AUTOSAR XML (schema 4-2-1)
standard types defined: boolean, float32, float64, sint16, sint32, sint8, uint16, uint32, uint64, uint8, boolean_CompuMethod, boolean_DataConstr, float32_DataConstr, float64_DataConstr, sint16_DataConstr, sint32_DataConstr, sint8_DataConstr, uint16_DataConstr, uint32_DataConstr, uint64_DataConstr, uint8_DataConstr
package /ComponentTypes
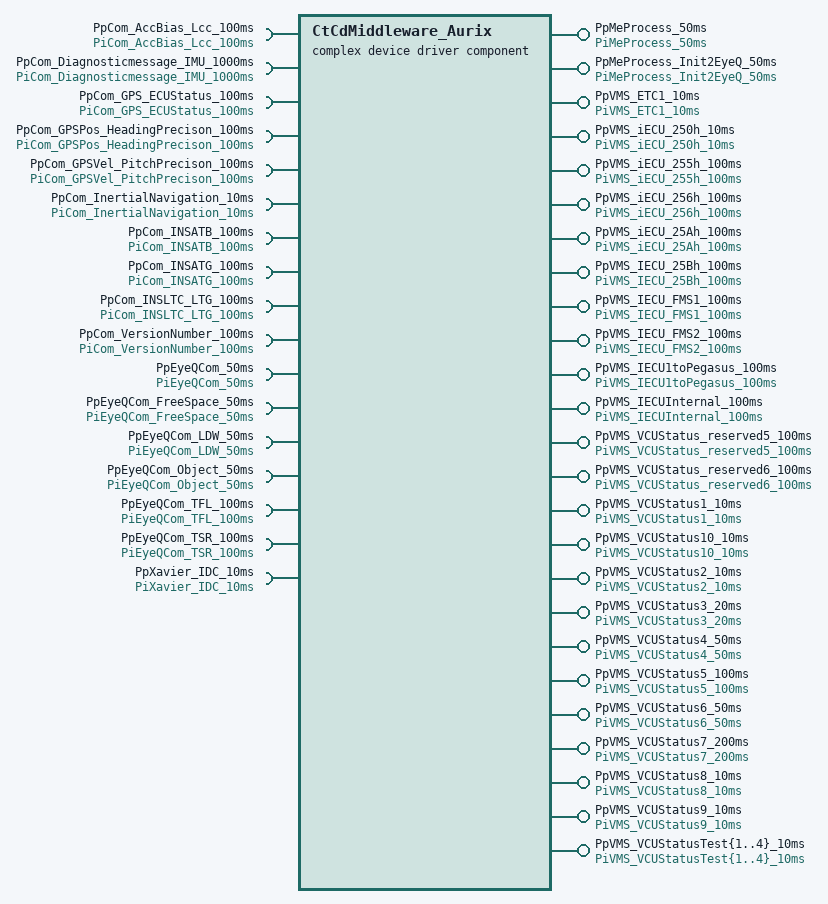
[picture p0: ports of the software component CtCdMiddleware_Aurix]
  complex device driver sw component type CtCdMiddleware_Aurix
    28 x provide port:
      PpMeProcess_50ms: provided-interface=PiMeProcess_50ms
        provided-com-specs:
          data-element=DeCurrentMode, init-value=constant-reference=C_RECORD_CurrentMode
          data-element=DeStartCalibration, init-value=0
      PpMeProcess_Init2EyeQ_50ms: provided-interface=PiMeProcess_Init2EyeQ_50ms
        provided-com-specs:
          data-element=DeCodingEnviroment, init-value=constant-reference=C_RECORD_CodingEnviroment
          data-element=DeIintISPCCoreVision, init-value=constant-reference=C_RECORD_IintISPCCoreVision
          data-element=DeInitEnvironment, init-value=constant-reference=C_RECORD_InitEnvironment
          data-element=DeInitGENERAL, init-value=constant-reference=C_RECORD_InitGENERAL
          data-element=DeInitTAC2, init-value=constant-reference=C_RECORD_TAC2
      PpVMS_ETC1_10ms: nonqueued-sender-com-spec{data-element=DeETC1, init-value=constant-reference=C_RECORD_ETC1}, provided-interface=PiVMS_ETC1_10ms
      PpVMS_iECU_250h_10ms: nonqueued-sender-com-spec{data-element=DeiECU_250h, init-value=constant-reference=C_RECORD_iECU_250h}, provided-interface=PiVMS_iECU_250h_10ms
      PpVMS_iECU_255h_100ms: nonqueued-sender-com-spec{data-element=DeiECU_255h, init-value=constant-reference=C_RECORD_iECU_255h}, provided-interface=PiVMS_iECU_255h_100ms
      PpVMS_iECU_256h_100ms: nonqueued-sender-com-spec{data-element=DeiECU_256h, init-value=constant-reference=C_RECORD_iECU_256h}, provided-interface=PiVMS_iECU_256h_100ms
      PpVMS_iECU_25Ah_100ms: nonqueued-sender-com-spec{data-element=DeiECU_25Ah, init-value=constant-reference=C_RECORD_iECU_25Ah}, provided-interface=PiVMS_iECU_25Ah_100ms
      PpVMS_IECU_25Bh_100ms: nonqueued-sender-com-spec{data-element=DeIECU_25Bh, init-value=constant-reference=C_RECORD_IECU_25Bh}, provided-interface=PiVMS_IECU_25Bh_100ms
      PpVMS_IECU_FMS1_100ms: nonqueued-sender-com-spec{data-element=DeIECU_FMS1, init-value=constant-reference=C_RECORD_IECU_FMS1}, provided-interface=PiVMS_IECU_FMS1_100ms
      PpVMS_IECU_FMS2_100ms: nonqueued-sender-com-spec{data-element=DeIECU_FMS2, init-value=constant-reference=C_RECORD_IECU_FMS2}, provided-interface=PiVMS_IECU_FMS2_100ms
      PpVMS_IECU1toPegasus_100ms: nonqueued-sender-com-spec{data-element=DeIECU1toPegasus, init-value=constant-reference=C_RECORD_IECU1toPegasus}, provided-interface=PiVMS_IECU1toPegasus_100ms
      PpVMS_IECUInternal_100ms: nonqueued-sender-com-spec{data-element=DeIECUInternal, init-value=constant-reference=C_RECORD_IECUInternal}, provided-interface=PiVMS_IECUInternal_100ms
      PpVMS_VCUStatus_reserved5_100ms: nonqueued-sender-com-spec{data-element=DeVCUStatus_reserved5, init-value=constant-reference=C_RECORD_VCUStatus_reserved5}, provided-interface=PiVMS_VCUStatus_reserved5_100ms
      PpVMS_VCUStatus_reserved6_100ms: nonqueued-sender-com-spec{data-element=DeVCUStatus_reserved6, init-value=constant-reference=C_RECORD_VCUStatus_reserved6}, provided-interface=PiVMS_VCUStatus_reserved6_100ms
      PpVMS_VCUStatus1_10ms: nonqueued-sender-com-spec{data-element=DeVCUStatus1, init-value=constant-reference=C_RECORD_VCUStatus1}, provided-interface=PiVMS_VCUStatus1_10ms
      PpVMS_VCUStatus10_10ms: nonqueued-sender-com-spec{data-element=DeVCUStatus10, init-value=constant-reference=C_RECORD_VCUStatus10}, provided-interface=PiVMS_VCUStatus10_10ms
      PpVMS_VCUStatus2_10ms: nonqueued-sender-com-spec{data-element=DeVCUStatus2, init-value=constant-reference=C_RECORD_VCUStatus2}, provided-interface=PiVMS_VCUStatus2_10ms
      PpVMS_VCUStatus3_20ms: nonqueued-sender-com-spec{data-element=DeVCUStatus3, init-value=constant-reference=C_RECORD_VCUStatus3}, provided-interface=PiVMS_VCUStatus3_20ms
      PpVMS_VCUStatus4_50ms: nonqueued-sender-com-spec{data-element=DeVCUStatus4, init-value=constant-reference=C_RECORD_VCUStatus4}, provided-interface=PiVMS_VCUStatus4_50ms
      PpVMS_VCUStatus5_100ms: nonqueued-sender-com-spec{data-element=DeVCUStatus5, init-value=constant-reference=C_RECORD_VCUStatus5}, provided-interface=PiVMS_VCUStatus5_100ms
      PpVMS_VCUStatus6_50ms: nonqueued-sender-com-spec{data-element=DeVCUStatus6, init-value=constant-reference=C_RECORD_VCUStatus6}, provided-interface=PiVMS_VCUStatus6_50ms
      PpVMS_VCUStatus7_200ms: nonqueued-sender-com-spec{data-element=DeVCUStatus7, init-value=constant-reference=C_RECORD_VCUStatus7}, provided-interface=PiVMS_VCUStatus7_200ms
      PpVMS_VCUStatus8_10ms: nonqueued-sender-com-spec{data-element=DeVCUStatus8, init-value=constant-reference=C_RECORD_VCUStatus8}, provided-interface=PiVMS_VCUStatus8_10ms
      PpVMS_VCUStatus9_10ms: nonqueued-sender-com-spec{data-element=DeVCUStatus9, init-value=constant-reference=C_RECORD_VCUStatus9}, provided-interface=PiVMS_VCUStatus9_10ms
      PpVMS_VCUStatusTest{1..4}_10ms: nonqueued-sender-com-spec{data-element=DeVCUStatusTest{1..4}, init-value=constant-reference=C_RECORD_VCUStatusTest{1..4}}, provided-interface=PiVMS_VCUStatusTest{1..4}_10ms
    17 x require port:
      PpCom_AccBias_Lcc_100ms: nonqueued-receiver-com-spec{data-element=DeAccBias_Lcc, filter=data-filter-type=ALWAYS, init-value=constant-reference=C_RECORD_AccBias_Lcc}, required-interface=PiCom_AccBias_Lcc_100ms
      PpCom_Diagnosticmessage_IMU_1000ms: nonqueued-receiver-com-spec{data-element=DeDiagnosticmessage_IMU, filter=data-filter-type=ALWAYS, init-value=constant-reference=C_RECORD_Diagnosticmessage_IMU}, required-interface=PiCom_Diagnosticmessage_IMU_1000ms
      PpCom_GPS_ECUStatus_100ms: nonqueued-receiver-com-spec{data-element=DeGPS_ECUStatus, filter=data-filter-type=ALWAYS, init-value=constant-reference=C_RECORD_GPS_ECUStatus}, required-interface=PiCom_GPS_ECUStatus_100ms
      PpCom_GPSPos_HeadingPrecison_100ms: nonqueued-receiver-com-spec{data-element=DeGPSPos_HeadingPrecison, filter=data-filter-type=ALWAYS, init-value=constant-reference=C_RECORD_GPSPos_HeadingPrecison}, required-interface=PiCom_GPSPos_HeadingPrecison_100ms
      PpCom_GPSVel_PitchPrecison_100ms: nonqueued-receiver-com-spec{data-element=DeGPSVel_PitchPrecison, filter=data-filter-type=ALWAYS, init-value=constant-reference=C_RECORD_GPSVel_PitchPrecison}, required-interface=PiCom_GPSVel_PitchPrecison_100ms
      PpCom_InertialNavigation_10ms: nonqueued-receiver-com-spec{data-element=DeInertialNavigation, filter=data-filter-type=ALWAYS, init-value=constant-reference=C_RECORD_InertialNavigation}, required-interface=PiCom_InertialNavigation_10ms
      PpCom_INSATB_100ms: nonqueued-receiver-com-spec{data-element=DeINSATB, filter=data-filter-type=ALWAYS, init-value=constant-reference=C_RECORD_INSATB}, required-interface=PiCom_INSATB_100ms
      PpCom_INSATG_100ms: nonqueued-receiver-com-spec{data-element=DeINSATG, filter=data-filter-type=ALWAYS, init-value=constant-reference=C_RECORD_INSATG}, required-interface=PiCom_INSATG_100ms
      PpCom_INSLTC_LTG_100ms: nonqueued-receiver-com-spec{data-element=DeINSLTC_LTG, filter=data-filter-type=ALWAYS, init-value=constant-reference=C_RECORD_INSLTC_LTG}, required-interface=PiCom_INSLTC_LTG_100ms
      PpCom_VersionNumber_100ms: nonqueued-receiver-com-spec{data-element=DeVersionNumber, filter=data-filter-type=ALWAYS, init-value=constant-reference=C_RECORD_VersionNumber}, required-interface=PiCom_VersionNumber_100ms
      PpEyeQCom_50ms: required-interface=PiEyeQCom_50ms
        required-com-specs:
          data-element=DeMeCommon_E, filter=data-filter-type=ALWAYS, init-value=constant-reference=C_RECORD_MeCommon_E
          data-element=DeMeConstructionArea_E, filter=data-filter-type=ALWAYS, init-value=constant-reference=C_RECORD_ConstructionArea_E
          data-element=DeMeHLB_E, filter=data-filter-type=ALWAYS, init-value=constant-reference=C_RECORD_HLB_E
          data-element=DeMeLane_Support_E, filter=data-filter-type=ALWAYS, init-value=constant-reference=C_RECORD_Lane_Support_E
          data-element=DeMeLaneAssignment_E, filter=data-filter-type=ALWAYS, init-value=constant-reference=C_RECORD_MeLaneAssignment
          data-element=PiEyeQCom_50ms/DeMeLDW_E, filter=data-filter-type=ALWAYS, init-value=constant-reference=C_RECORD_LDW_E
          data-element=DeMeLS_ADV_E, filter=data-filter-type=ALWAYS, init-value=constant-reference=C_RECORD_MeLS_ADV_E
          data-element=DeMeLS_Road_Edge_E, filter=data-filter-type=ALWAYS, init-value=constant-reference=C_RECORD_LS_Road_Edge_E
          data-element=DeMeSematicLines_E, filter=data-filter-type=ALWAYS, init-value=constant-reference=C_RECORD_MeSematicLines_E
          data-element=DeMeSematicMarks_E, filter=data-filter-type=ALWAYS, init-value=constant-reference=C_RECORD_MeSematicMark_E
          data-element=DeMeSL_Descrip_E, filter=data-filter-type=ALWAYS, init-value=constant-reference=C_RECORD_SL_Descrip_E
          data-element=DeRequestCalibrationStatus, filter=data-filter-type=ALWAYS, init-value=constant-reference=C_RequestCalibrationStatus
      PpEyeQCom_FreeSpace_50ms: required-interface=PiEyeQCom_FreeSpace_50ms
        required-com-specs:
          data-element=DeMeFreeSpace_E, filter=data-filter-type=ALWAYS, init-value=constant-reference=C_RECORD_MeFreeSpace_E
          data-element=DeMeFreeSpace_E_{1..5}, filter=data-filter-type=ALWAYS, init-value=constant-reference=C_RECORD_MeFreeSpace_E_x
      PpEyeQCom_LDW_50ms: nonqueued-receiver-com-spec{data-element=PiEyeQCom_LDW_50ms/DeMeLDW_E, filter=data-filter-type=ALWAYS, init-value=constant-reference=C_RECORD_MeLDW_E}, required-interface=PiEyeQCom_LDW_50ms
      PpEyeQCom_Object_50ms: required-interface=PiEyeQCom_Object_50ms
        required-com-specs:
          data-element=DeMeObjects_E, filter=data-filter-type=ALWAYS, init-value=constant-reference=C_RECORD_MeObjects_E
          data-element=DeMeObjects_E_{1..4}, filter=data-filter-type=ALWAYS, init-value=constant-reference=C_RECORD_MeObjects_E_x
      PpEyeQCom_TFL_100ms: nonqueued-receiver-com-spec{data-element=DeMeTFL, filter=data-filter-type=ALWAYS, init-value=constant-reference=C_RECORD_MeTFL_E}, required-interface=PiEyeQCom_TFL_100ms
      PpEyeQCom_TSR_100ms: required-interface=PiEyeQCom_TSR_100ms
        required-com-specs:
          data-element=DeMeTSR, filter=data-filter-type=ALWAYS, init-value=constant-reference=C_RECORD_MeTSR_E
          data-element=DeMeTSR_1, filter=data-filter-type=ALWAYS, init-value=constant-reference=C_RECORD_MeTSR_E_x
          data-element=DeMeTSR_2, filter=data-filter-type=ALWAYS, init-value=constant-reference=C_RECORD_MeTSR_E_x
      PpXavier_IDC_10ms: nonqueued-receiver-com-spec{data-element=DeIDC, filter=data-filter-type=ALWAYS, init-value=constant-reference=C_RECORD_IDC}, required-interface=PiXavier_IDC_10ms
    behavior CtCdMiddleware_Aurix_InternalBehavior
      7 x timing event:
        TMT_RCtCdMiddleware_Aurix_1000ms: start-on-event=RCtCdMiddleware_Aurix_1000ms, period=1
        TMT_RCtCdMiddleware_Aurix_100ms: start-on-event=RCtCdMiddleware_Aurix_100ms, period=0.1
        TMT_RCtCdMiddleware_Aurix_10ms: start-on-event=RCtCdMiddleware_Aurix_10ms, period=0.01
        TMT_RCtCdMiddleware_Aurix_200ms: start-on-event=RCtCdMiddleware_Aurix_200ms, period=0.2
        TMT_RCtCdMiddleware_Aurix_20ms: start-on-event=RCtCdMiddleware_Aurix_20ms, period=0.02
        TMT_RCtCdMiddleware_Aurix_30ms: start-on-event=RCtCdMiddleware_Aurix_30ms, period=0.03
        TMT_RCtCdMiddleware_Aurix_50ms: start-on-event=RCtCdMiddleware_Aurix_50ms, period=0.05
      7 x runnable:
        RCtCdMiddleware_Aurix_1000ms
          data-receive-point-by-arguments:
            access REC_PiCom_Diagnosticmessage_IMU_1000ms_DeDiagnosticmessage_IMU: accessed-variable=PpCom_Diagnosticmessage_IMU_1000ms.DeDiagnosticmessage_IMU
        RCtCdMiddleware_Aurix_100ms
          data-receive-point-by-arguments:
            12 x access:
              REC_PiCom_AccBias_Lcc_100ms_DeAccBias_Lcc: accessed-variable=PpCom_AccBias_Lcc_100ms.DeAccBias_Lcc
              REC_PiCom_GPS_ECUStatus_100ms_DeGPS_ECUStatus: accessed-variable=PpCom_GPS_ECUStatus_100ms.DeGPS_ECUStatus
              REC_PiCom_GPSPos_HeadingPrecison_100ms_DeGPSPos_HeadingPrecison: accessed-variable=PpCom_GPSPos_HeadingPrecison_100ms.DeGPSPos_HeadingPrecison
              REC_PiCom_GPSVel_PitchPrecison_100ms_DeGPSVel_PitchPrecison: accessed-variable=PpCom_GPSVel_PitchPrecison_100ms.DeGPSVel_PitchPrecison
              REC_PiCom_INSATB_100ms_DeINSATB: accessed-variable=PpCom_INSATB_100ms.DeINSATB
              REC_PiCom_INSATG_100ms_DeINSATG: accessed-variable=PpCom_INSATG_100ms.DeINSATG
              REC_PiCom_INSLTC_LTG_100ms_DeINSLTC_LTG: accessed-variable=PpCom_INSLTC_LTG_100ms.DeINSLTC_LTG
              REC_PiCom_VersionNumber_100ms_DeVersionNumber: accessed-variable=PpCom_VersionNumber_100ms.DeVersionNumber
              REC_PiEyeQCom_TFL_100ms_DeMeTFL: accessed-variable=PpEyeQCom_TFL_100ms.DeMeTFL
              REC_PiEyeQCom_TSR_100ms_DeMeTSR: accessed-variable=PpEyeQCom_TSR_100ms.DeMeTSR
              REC_PiEyeQCom_TSR_100ms_DeMeTSR_1: accessed-variable=PpEyeQCom_TSR_100ms.DeMeTSR_1
              REC_PiEyeQCom_TSR_100ms_DeMeTSR_2: accessed-variable=PpEyeQCom_TSR_100ms.DeMeTSR_2
          data-send-points:
            11 x access:
              SEND_PiVMS_iECU_255h_100ms_DeiECU_255h: accessed-variable=PpVMS_iECU_255h_100ms.DeiECU_255h
              SEND_PiVMS_iECU_256h_100ms_DeiECU_256h: accessed-variable=PpVMS_iECU_256h_100ms.DeiECU_256h
              SEND_PiVMS_iECU_25Ah_100ms_DeiECU_25Ah: accessed-variable=PpVMS_iECU_25Ah_100ms.DeiECU_25Ah
              SEND_PiVMS_IECU_25Bh_100ms_DeIECU_25Bh: accessed-variable=PpVMS_IECU_25Bh_100ms.DeIECU_25Bh
              SEND_PiVMS_IECU_FMS1_100ms_DeIECU_FMS1: accessed-variable=PpVMS_IECU_FMS1_100ms.DeIECU_FMS1
              SEND_PiVMS_IECU_FMS2_100ms_DeIECU_FMS2: accessed-variable=PpVMS_IECU_FMS2_100ms.DeIECU_FMS2
              SEND_PiVMS_IECU1toPegasus_100ms_DeIECU1toPegasus: accessed-variable=PpVMS_IECU1toPegasus_100ms.DeIECU1toPegasus
              SEND_PiVMS_IECUInternal_100ms_DeIECUInternal: accessed-variable=PpVMS_IECUInternal_100ms.DeIECUInternal
              SEND_PiVMS_VCUStatus_reserved5_100ms_DeVCUStatus_reserved5: accessed-variable=PpVMS_VCUStatus_reserved5_100ms.DeVCUStatus_reserved5
              SEND_PiVMS_VCUStatus_reserved6_100ms_DeVCUStatus_reserved6: accessed-variable=PpVMS_VCUStatus_reserved6_100ms.DeVCUStatus_reserved6
              SEND_PiVMS_VCUStatus5_100ms_DeVCUStatus5: accessed-variable=PpVMS_VCUStatus5_100ms.DeVCUStatus5
        RCtCdMiddleware_Aurix_10ms
          data-receive-point-by-arguments:
            access REC_PiCom_InertialNavigation_10ms_DeInertialNavigation: accessed-variable=PpCom_InertialNavigation_10ms.DeInertialNavigation
            access REC_PiXavier_IDC_10ms_DeIDC: accessed-variable=PpXavier_IDC_10ms.DeIDC
          data-send-points:
            11 x access:
              SEND_PiVMS_ETC1_10ms_DeETC1: accessed-variable=PpVMS_ETC1_10ms.DeETC1
              SEND_PiVMS_iECU_250h_10ms_DeiECU_250h: accessed-variable=PpVMS_iECU_250h_10ms.DeiECU_250h
              SEND_PiVMS_VCUStatus1_10ms_DeVCUStatus1: accessed-variable=PpVMS_VCUStatus1_10ms.DeVCUStatus1
              SEND_PiVMS_VCUStatus10_10ms_DeVCUStatus10: accessed-variable=PpVMS_VCUStatus10_10ms.DeVCUStatus10
              SEND_PiVMS_VCUStatus2_10ms_DeVCUStatus2: accessed-variable=PpVMS_VCUStatus2_10ms.DeVCUStatus2
              SEND_PiVMS_VCUStatus8_10ms_DeVCUStatus8: accessed-variable=PpVMS_VCUStatus8_10ms.DeVCUStatus8
              SEND_PiVMS_VCUStatus9_10ms_DeVCUStatus9: accessed-variable=PpVMS_VCUStatus9_10ms.DeVCUStatus9
              SEND_PiVMS_VCUStatusTest{1..4}_10ms_DeVCUStatusTest{1..4}: accessed-variable=PpVMS_VCUStatusTest{1..4}_10ms.DeVCUStatusTest{1..4}
        RCtCdMiddleware_Aurix_200ms
          data-send-points:
            access SEND_PiVMS_VCUStatus7_200ms_DeVCUStatus7: accessed-variable=PpVMS_VCUStatus7_200ms.DeVCUStatus7
        RCtCdMiddleware_Aurix_20ms
          data-send-points:
            access SEND_PiVMS_VCUStatus3_20ms_DeVCUStatus3: accessed-variable=PpVMS_VCUStatus3_20ms.DeVCUStatus3
        RCtCdMiddleware_Aurix_30ms
        RCtCdMiddleware_Aurix_50ms
          data-receive-point-by-arguments:
            24 x access:
              REC_PiEyeQCom_50ms_DeMeCommon_E: accessed-variable=PpEyeQCom_50ms.DeMeCommon_E
              REC_PiEyeQCom_50ms_DeMeConstructionArea_E: accessed-variable=PpEyeQCom_50ms.DeMeConstructionArea_E
              REC_PiEyeQCom_50ms_DeMeHLB_E: accessed-variable=PpEyeQCom_50ms.DeMeHLB_E
              REC_PiEyeQCom_50ms_DeMeLane_Support_E: accessed-variable=PpEyeQCom_50ms.DeMeLane_Support_E
              REC_PiEyeQCom_50ms_DeMeLaneAssignment_E: accessed-variable=PpEyeQCom_50ms.DeMeLaneAssignment_E
              REC_PiEyeQCom_50ms_DeMeLDW_E: accessed-variable=PpEyeQCom_50ms.DeMeLDW_E
              REC_PiEyeQCom_50ms_DeMeLS_ADV_E: accessed-variable=PpEyeQCom_50ms.DeMeLS_ADV_E
              REC_PiEyeQCom_50ms_DeMeLS_Road_Edge_E: accessed-variable=PpEyeQCom_50ms.DeMeLS_Road_Edge_E
              REC_PiEyeQCom_50ms_DeMeSematicLines_E: accessed-variable=PpEyeQCom_50ms.DeMeSematicLines_E
              REC_PiEyeQCom_50ms_DeMeSematicMarks_E: accessed-variable=PpEyeQCom_50ms.DeMeSematicMarks_E
              REC_PiEyeQCom_50ms_DeMeSL_Descrip_E: accessed-variable=PpEyeQCom_50ms.DeMeSL_Descrip_E
              REC_PiEyeQCom_50ms_DeRequestCalibrationStatus: accessed-variable=PpEyeQCom_50ms.DeRequestCalibrationStatus
              REC_PiEyeQCom_FreeSpace_50ms_DeMeFreeSpace_E: accessed-variable=PpEyeQCom_FreeSpace_50ms.DeMeFreeSpace_E
              REC_PiEyeQCom_FreeSpace_50ms_DeMeFreeSpace_E_{1..5}: accessed-variable=PpEyeQCom_FreeSpace_50ms.DeMeFreeSpace_E_{1..5}
              REC_PiEyeQCom_LDW_50ms_DeMeLDW_E: accessed-variable=PpEyeQCom_LDW_50ms.DeMeLDW_E
              REC_PiEyeQCom_Object_50ms_DeMeObjects_E: accessed-variable=PpEyeQCom_Object_50ms.DeMeObjects_E
              REC_PiEyeQCom_Object_50ms_DeMeObjects_E_{1..4}: accessed-variable=PpEyeQCom_Object_50ms.DeMeObjects_E_{1..4}
          data-send-points:
            9 x access:
              SEND_PiMeProcess_50ms_DeCurrentMode: accessed-variable=PpMeProcess_50ms.DeCurrentMode
              SEND_PiMeProcess_50ms_DeStartCalibration: accessed-variable=PpMeProcess_50ms.DeStartCalibration
              SEND_PiMeProcess_Init2EyeQ_50ms_DeCodingEnviroment: accessed-variable=PpMeProcess_Init2EyeQ_50ms.DeCodingEnviroment
              SEND_PiMeProcess_Init2EyeQ_50ms_DeIintISPCCoreVision: accessed-variable=PpMeProcess_Init2EyeQ_50ms.DeIintISPCCoreVision
              SEND_PiMeProcess_Init2EyeQ_50ms_DeInitEnvironment: accessed-variable=PpMeProcess_Init2EyeQ_50ms.DeInitEnvironment
              SEND_PiMeProcess_Init2EyeQ_50ms_DeInitGENERAL: accessed-variable=PpMeProcess_Init2EyeQ_50ms.DeInitGENERAL
              SEND_PiMeProcess_Init2EyeQ_50ms_DeInitTAC2: accessed-variable=PpMeProcess_Init2EyeQ_50ms.DeInitTAC2
              SEND_PiVMS_VCUStatus4_50ms_DeVCUStatus4: accessed-variable=PpVMS_VCUStatus4_50ms.DeVCUStatus4
              SEND_PiVMS_VCUStatus6_50ms_DeVCUStatus6: accessed-variable=PpVMS_VCUStatus6_50ms.DeVCUStatus6
  swc implementation CtCdMiddleware_Aurix_Implementation: behavior=CtCdMiddleware_Aurix_InternalBehavior
    code-descriptors:
      code Default: artifact-descriptors=autosar-engineering-object={short-label=Default, category=SWSRC}
package /Constants
  141 x constant specification:
    C_ARRAY_10_LaneAssignment: value-spec=10 x C_RECORD_LaneAssignment
    C_ARRAY_10_SematicLine: value-spec=10 x C_RECORD_SematicLine
    C_ARRAY_10_SLD: value-spec=10 x C_RECORD_SLD
    C_ARRAY_10_TFL: value-spec=10 x C_RECORD_TFL
    C_ARRAY_10_TSR: value-spec=10 x C_RECORD_TSR
    C_ARRAY_120_FSPoint: value-spec=120 x C_RECORD_FSPoint
    C_ARRAY_14_ConArea: value-spec=14 x C_RECORD_ConArea
    C_ARRAY_2_LS_Host_Line: value-spec=[C_RECORD_LS_Host_Line, C_RECORD_LS_Host_Line]
    C_ARRAY_20_MeObject: value-spec=20 x C_RECORD_MeObject
    C_ARRAY_20_SematicMark: value-spec=20 x C_RECORD_SematicMark
    C_ARRAY_20_TSR: value-spec=20 x C_RECORD_TSR
    C_ARRAY_24_FSPoint: value-spec=24 x C_RECORD_FSPoint
    C_ARRAY_4_LS_Adjacent_Line: value-spec=[C_RECORD_LS_Adjacent_Line, C_RECORD_LS_Adjacent_Line, C_RECORD_LS_Adjacent_Line, C_RECORD_LS_Adjacent_Line]
    C_ARRAY_4_LS_Road_Edge: value-spec=[C_RECORD_LS_Road_Edge, C_RECORD_LS_Road_Edge, C_RECORD_LS_Road_Edge, C_RECORD_LS_Road_Edge]
    C_ARRAY_5_MeObject: value-spec=5 x C_RECORD_MeObject
    C_ARRAY_8_MeLS_ADV_INTP: value-spec=8 x C_RECORD_MeLS_ADV_INTP
    C_ARRAY_UINT64_1_0: value-spec=[0, 0]
    C_RECORD_AccBias_Lcc: value-spec=fields=[AxBiassecinfo:0, AyBiassecinfo:0, AzBiassecinfo:0, Lccsecinfo:0]
    C_RECORD_Acce_AngularVel_X: value-spec=fields=[AccelerationXsecinfo:0, AngularRateXsecinfo:0]
    C_RECORD_Acce_AngularVel_Y: value-spec=fields=[AccelerationYsecinfo:0, AngularRateYsecinfo:0]
    C_RECORD_Acce_AngularVel_Z: value-spec=fields=[AccelerationZsecinfo:0, AngularRateZsecinfo:0]
    C_RECORD_ADVCommon: value-spec=fields=[LS_ADV_Zero_byte:0, LS_ADV_Protocol_Version:0, LS_ADV_Sync_ID:0, LS_INTP_Number:0, LS_CA_Is_Construction_Area:0, LS_Road_Vertical_Surface_Valid:0, Reserved_1:0, LS_Road_Vertical_Surface_VR:0, LS_Road_Vertical_Surface_C0:0, LS_Road_Vertical_Surface_C1:0, Reserved_2:0, PaddingGap8_1:0, PaddingGap16_2:0, PaddingGap16_3:0, PaddingGap16_4:0, LS_Road_Vertical_Surface_C2:0, Reserved_3:0, PaddingGap16_5:0, PaddingGap16_6:0, PaddingGap16_7:0, LS_Road_Vertical_Surface_C3:0, LS_Path_Pred_Valid:0, PaddingGap8_8:0, PaddingGap16_9:0, LS_Path_Pred_C0:0, Reserved_4:0, PaddingGap8_10:0, PaddingGap16_11:0, LS_Path_Pred_C1:0, LS_Path_Pred_C2:0, Reserved_5:0, PaddingGap16_12:0, PaddingGap16_13:0, LS_Path_Pred_C3:0, LS_Path_Pred_Conf:0, LS_Path_Pred_Half_Width:0, LS_INTP_Is_Highway_Merge_Left:0, LS_INTP_Is_Highway_Merge_Right:0, LS_INTP_Is_Highway_Exit_Left:0, LS_INTP_Is_Highway_Exit_Right:0, LS_INTP_Header_Buffer:0]
    C_RECORD_AtterrStatus2: value-spec=fields=[PitchStdsecinfo:0, RollStdsecinfo:0, VelDStdsecinfo:0, VelEStdsecinfo:0, VelNStdsecinfo:0, YawStdsecinfo:0]
    C_RECORD_CACommon: value-spec=fields=[CA_Zero_byte:0, CA_Protocol_Version:0, CA_Sync_ID:0, CA_Region_Code:0, CA_Objects_Count:0, PaddingGap16_1:0]
    C_RECORD_CodingEnviroment: value-spec=fields=[CEnvironment_Zero_byte:0, CEnvironment_Protocol_Version:0, PaddingGap16_1:0, CEnvironment_leftWheel:0, CEnvironment_rightWheel:0, CEnvironment_minHorizon_M:0, CEnvironment_maxHorizon_M:0, CEnvironment_minYaw_M:0, CEnvironment_maxYaw_M:0, Reserved_1:0, PaddingGap8_2:0, PaddingGap16_3:0, CEnvironment_camToRearAxle:0, CEnvironment_wheelRadius:0, Reserved_2:0, PaddingGap8_4:0, PaddingGap16_5:0, CEnvironment_refPX_Front_Bumper:0, CEnvironment_camToFrontAxle:0, CEnvironment_wheelWidth:0, CEnvironment_Max_Roll:0, Reserved_3:0, PaddingGap8_6:0, PaddingGap16_7:0]
    C_RECORD_ConArea: value-spec=fields=[CA_ID:0, CA_Frame_Age:0, CA_CA_Object_Type:0, PaddingGap8_1:0, CA_Long_Distance:0, CA_Long_DistancSTD:0, CA_Lat_Distance:0, CA_Lat_DistancSTD:0, CA_Height:0, CA_Height_STD:0, CA_Object_Height:0, CA_Object_Height_STD:0, CA_Object_Width:0, CA_Object_Width_STD:0, CA_Buffer:0, PaddingGap8_2:0, Reserved_1:0, Reserved_2:0, Reserved_3:0, Reserved_4:0, PaddingGap8_3:0]
    C_RECORD_ConstructionArea_E: value-spec=fields=[{short-label=stHeader, constant=C_RECORD_HEADER}, {short-label=stCACommon, constant=C_RECORD_CACommon}, {short-label=gstConArea, constant=C_ARRAY_14_ConArea}]
    C_RECORD_CurrentMode: value-spec=fields=[{short-label=stHeader, constant=C_RECORD_HEADER}, CurrentMode:0, PaddingGap8_1:0, PaddingGap16_2:0]
    C_RECORD_Diagnosticmessage_IMU: value-spec=fields=[DiffDataLinkBrokensecinfo:0, GNSSAntenasBrokensecinfo:0, GPSMsgErrInIMUsecinfo:0, IECUMsgErrInIMUsecinfo:0]
    C_RECORD_ETC1: value-spec=fields=[SrcAddressCtrlDeviceForTransCtrl:0, TransInputShaftSpeed:0, ProgressiveShiftDisable:0, EngineMomentaryOverspeedEnable:0, PercentClutchSlip:0, TransOutputShaftSpeed:0, TransShiftlnProcess:0, TransTorqueConverterLockupEngag:0, TransDrivelineEngaged:0]
    C_RECORD_FSPCommon: value-spec=fields=[FSP_Zero_byte:0, FSP_Protocol_Version:0, FSP_Sync_ID:0, FSP_Num_Of_Obstacles:0, Reserved_1:0, PaddingGap16_1:0]
    C_RECORD_FSPoint: value-spec=fields=[FSP_ID:0, FSP_Is_Valid:0, PaddingGap8_1:0, FSP_Existence_Prob:0, FSP_Emptiness_Prob:0, FSP_Classification_Type:0, FSP_Mobility_Status:0, PaddingGap16_2:0, FSP_Range:0, Reserved_2:0, PaddingGap16_3:0, FSP_Range_STD:0, FSP_Height:0, FSP_Height_STD:0, PaddingGap16_4:0, PaddingGap16_5:0, FSP_Azimuth_Angle:0, FSP_Buffer:0, PaddingGap16_6:0, PaddingGap16_7:0, PaddingGap16_8:0]
    C_RECORD_GPS_ECUStatus: value-spec=fields=[ECUWarningsecinfo:0, GPSHeadingStatussecinfo:0, GPSPosStatussecinfo:0, GPSStatussecinfo:0, GPSVelStatussecinfo:0, GPSWarningsecinfo:0, RTKDelaysecinfo:0, VehiclesStatussecinfo:0]
    C_RECORD_GPSPos_HeadingPrecison: value-spec=fields=[AltSigmaGPSsecinfo:0, HeadingSigmaGPSsecinfo:0, LatSigmaGPSsecinfo:0, LonSigmaGPSsecinfo:0]
    C_RECORD_GPSVel_PitchPrecison: value-spec=fields=[PitchSigmaGPSsecinfo:0, VeldownsigmaGPSsecinfo:0, VeleastsigmaGPSsecinfo:0, VelnorthsigmaGPSsecinfo:0]
    C_RECORD_HEADER: value-spec=fields=[{short-label=TimeStamp, constant=C_ARRAY_UINT64_1_0}, FrameID:0, PaddingGap8_1:0, Counter:0]
    C_RECORD_HLB_E: value-spec=fields=[HLB_Zero_byte:0, HLB_Protocol_Version:0, HLB_Sync_ID:0, HLB_Running_Mode:0, HLB_InActive_Reason:0, HLB_Decision:0, Reserved_1:0, PaddingGap8_1:0, HLB_Reason:0]
    C_RECORD_IDC: value-spec=fields=[{short-label=IDCDTC, constant=C_RECORD_IDCDTC}, {short-label=IDCStatus1, constant=C_RECORD_IDCStatus1}, {short-label=IDCStatus2, constant=C_RECORD_IDCStatus2}, {short-label=IDCStatus3, constant=C_RECORD_IDCStatus3}, {short-label=IDCStatus4, constant=C_RECORD_IDCStatus4}, {short-label=IDCStatus5, constant=C_RECORD_IDCStatus5}, {short-label=IDCStatus6, constant=C_RECORD_IDCStatus6}, {short-label=IDCStatus7, constant=C_RECORD_IDCStatus7}, {short-label=IDCStatus8, constant=C_RECORD_IDCStatus8}, {short-label=IDCStatus9, constant=C_RECORD_IDCStatus9}, {short-label=IDCStatus40, constant=C_RECORD_IDCStatus40}, {short-label=IDCStatus41, constant=C_RECORD_IDCStatus41}, {short-label=IDCStatus42, constant=C_RECORD_IDCStatus42}, {short-label=IDCStatus43, constant=C_RECORD_IDCStatus43}, {short-label=IDCStatus91, constant=C_RECORD_IDCStatus91}, {short-label=IDCStatus92, constant=C_RECORD_IDCStatus92}, {short-label=IDCStatus93, constant=C_RECORD_IDCStatus93}, {short-label=IDCStatus_reserved1, constant=C_RECORD_IDCStatus_reserved1}, {short-label=IDCStatus_reserved2, constant=C_RECORD_IDCStatus_reserved2}, {short-label=IDCStatus_reserved3, constant=C_RECORD_IDCStatus_reserved3}, {short-label=IDCStatus_reserved4, constant=C_RECORD_IDCStatus_reserved4}, {short-label=IDCStatus_reserved5, constant=C_RECORD_IDCStatus_reserved5}, {short-label=IDCStatus_reserved6, constant=C_RECORD_IDCStatus_reserved6}]
    C_RECORD_IDCDTC: value-spec=fields=[FailureBitPegsusInternal:0, FailureBitODFSPegsus:0, FailureBitODFSIECU2:0, FailureBitLoc:0]
    C_RECORD_IDCStatus_reserved1: value-spec=fields=[Byte_1:0, Byte_0:0]
    C_RECORD_IDCStatus_reserved2: value-spec=fields=[Byte_3:0, Byte_2:0]
    C_RECORD_IDCStatus_reserved3: value-spec=fields=[Byte_5:0, Byte_4:0]
    C_RECORD_IDCStatus_reserved4: value-spec=fields=[Byte_7:0, Byte_6:0]
    C_RECORD_IDCStatus_reserved5: value-spec=fields=[Byte_9:0, Byte_8:0]
    C_RECORD_IDCStatus_reserved6: value-spec=fields=[Byte_11:0, Byte_10:0]
    C_RECORD_IDCStatus1: value-spec=fields=[RoadFollowErrorHSC4:0, StrgWhlAngGrdCmdHSC4:0, StrgWhlAngCmdVHSC4:0, StrgWhlAngCmdHSC4:0, VehDeceCmdVHSC4:0, VehDeceCmdHSC4:0, EngToqReqVHSC4:0, EngToqReqHSC4:0, IDCReadyHSC4:0]
    C_RECORD_IDCStatus2: value-spec=fields=[Request_Auto:0, APP_Status:0, APACtlCmd:0, VehSpdMaxLmtHSC4:0, IDCDriveEnvironmentHSC4:0, ShifterPosReqHSC4:0, VehSpdReqHSC4:0, ActualYHSC4:0, ActualXHSC4:0]
    C_RECORD_IDCStatus3: value-spec=fields=[YawRateHSC4:0, HeadingAngleHSC4:0, LateralAcceHSC4:0, LongitudinalAcceHSC4:0]
    C_RECORD_IDCStatus4: value-spec=fields=[LongtAccReqHSC4:0, TrackCoefficiantX2VHSC4:0, TrackCoefficiantX2HSC4:0, TrackCoefficiantX1VHSC4:0, TrackCoefficiantX1HSC4:0]
    C_RECORD_IDCStatus40: value-spec=fields=[TrackCoefficiantX2HSC4_QJ:0, TrackCoefficiantX1HSC4_QJ:0]
    C_RECORD_IDCStatus41: value-spec=fields=[TrackCoefficiantX4HSC4_QJ:0, TrackCoefficiantX3HSC4_QJ:0]
    C_RECORD_IDCStatus42: value-spec=fields=[TrackCoefficiantX5HSC4_QJ:0, TrackCoefficiantY2HSC4_QJ:0, TrackCoefficiantY1HSC4_QJ:0]
    C_RECORD_IDCStatus43: value-spec=fields=[TrackCoefficiantY5HSC4_QJ:0, TrackCoefficiantY4HSC4_QJ:0, TrackCoefficiantY3HSC4_QJ:0]
    C_RECORD_IDCStatus5: value-spec=fields=[INSSlopeHSC4:0, TrackCoefficiantX4VHSC4:0, TrackCoefficiantX4HSC4:0, TrackCoefficiantX3HSC4:0, TrackCoefficiantX3VHSC4:0]
    C_RECORD_IDCStatus6: value-spec=fields=[TrackCoefficiantX5VHSC4:0, TrackCoefficiantX5HSC4:0, TrackCoefficiantY2VHSC4:0, TrackCoefficiantY2HSC4:0, TrackCoefficiantY1VHSC4:0, TrackCoefficiantY1HSC4:0]
    C_RECORD_IDCStatus7: value-spec=fields=[TrackCoefficiantY5HSC4:0, TrackCoefficiantY5VHSC4:0, TrackCoefficiantY4VHSC4:0, TrackCoefficiantY4HSC4:0, TrackCoefficiantY3VHSC4:0, TrackCoefficiantY3HSC4:0]
    C_RECORD_IDCStatus8: value-spec=fields=[DistanceToStop:0, Parmtrobg2HSC4:0, Parmtrobg1HSC4:0, BrkLghtsCmdHSC4:0, DangerousWrnngLghtCmdHSC4:0, DipdBeamLampsCmdHSC4:0, FrtFogLampCmdHSC4:0, HornCmdHSC4:0, LDircnLampsCmdHSC4:0, MainBeamLampsCmdHSC4:0, RDircnLampsCmdHSC4:0, RevsngLghtCmdHSC4:0, RrFogLampCmdHSC4:0, WidthLmpTaillightCmdHSC4:0, WiperCmdHSC4:0, WshrCmdHSC4:0]
    C_RECORD_IDCStatus9: value-spec=fields=GPSAngleHSC4:0
    C_RECORD_IDCStatus91: value-spec=fields=GPSLatitudeHSC4:8 x 0
    C_RECORD_IDCStatus92: value-spec=fields=GPSLongitudeHSC4:8 x 0
    C_RECORD_IDCStatus93: value-spec=fields=[RounterChangeHSC4:0, PathRadiumAvgHSC4:0, IDCAlvRCHSC4:0, CurveValidHSC4:0, PathRadiumMinHSC4:0, PredictedLengthHSC4:0]
    C_RECORD_iECU_250h: value-spec=fields=SA_AngleValue:0
    C_RECORD_iECU_255h: value-spec=fields=[iECU_PEGSUS_pilotWarning:0, iECU_PEGSUS_pilotStatus:0, iECU_pilotDisableInfo:0, iECU_pilot_OverrideIndicator:0]
    C_RECORD_iECU_256h: value-spec=fields=iECU_pilot_Steer_Override:0
    C_RECORD_iECU_25Ah: value-spec=fields=iECU_PEGSUS_AEBState:0
    C_RECORD_IECU_25Bh: value-spec=fields=LockandTwistSwitch:0
    C_RECORD_IECU_FMS1: value-spec=fields=[HighResolutionTripDistance_FMS:0, HghRsolTotalVehDistance_FMS:0]
    C_RECORD_IECU_FMS2: value-spec=fields=[Byte7:0, ResidualLiquidLevel_FMS:0]
    C_RECORD_IECU1toPegasus: value-spec=fields=[FailureBitODFSIECU1:0, FailureBitActor01:0]
    C_RECORD_IECUInternal: value-spec=fields=[Byte3:0, FailureBitIECU1Internal:0]
    C_RECORD_IintISPCCoreVision: value-spec=fields=[ISPC_Zero_byte:0, ISPC_Protocol_Version:0, Reserved_1:0, IVISION_Protocol_Version:0, IVISION_Zero_byte:0, Reserved_2:0, PaddingGap16_1:0]
    C_RECORD_InertialNavigation: value-spec=fields=[{short-label=Acce_AngularVel_X, constant=C_RECORD_Acce_AngularVel_X}, {short-label=Acce_AngularVel_Y, constant=C_RECORD_Acce_AngularVel_Y}, {short-label=Acce_AngularVel_Z, constant=C_RECORD_Acce_AngularVel_Z}, {short-label=AtterrStatus2, constant=C_RECORD_AtterrStatus2}, {short-label=INSAltitude_VelDown, constant=C_RECORD_INSAltitude_VelDown}, {short-label=INSLatitudeInfo, constant=C_RECORD_INSLatitudeInfo}, {short-label=INSLongitudeInfo, constant=C_RECORD_INSLongitudeInfo}, {short-label=NavStatus_Heading, constant=C_RECORD_NavStatus_Heading}, {short-label=Pitch_Roll, constant=C_RECORD_Pitch_Roll}, {short-label=PoserrStatus1, constant=C_RECORD_PoserrStatus1}, {short-label=StatusInfo, constant=C_RECORD_StatusInfo}, {short-label=VelNorthEast, constant=C_RECORD_VelNorthEast}]
    C_RECORD_InitEnvironment: value-spec=fields=[IEnvironment_Zero_byte:0, IEnvironment_General_Version:0, PaddingGap16_1:0, IEnvironment_leftWheel:0, IEnvironment_rightWheel:0, IEnvironment_refPX_Front_Bumper:0, IEnvironment_camToFrontAxle:0, IEnvironment_camToRearAxle:0, IEnvironment_wheelWidth:0, IEnvironment_wheelRadius:0, IEnvironment_minHorizon_M:0, IEnvironment_maxHorizon_M:0, IEnvironment_minYaw_M:0, IEnvironment_maxYaw_M:0, Reserved_1:0, Reserved_2:0, PaddingGap16_2:0, IEnvironment_Max_Roll:0, Reserved_3:0, PaddingGap8_3:0, PaddingGap16_4:0]
    C_RECORD_InitGENERAL: value-spec=fields=[IGeneral_Zero_byte:0, IGeneral_Vision_Protocol_Version:0, IGeneral_Region_Code:0, IGeneral_Driving_Side:0, IGeneral_Pitch:0, IGeneral_Yaw:0, IGeneral_Roll_Angle:0, IGeneral_Cam_Height:0, Reserved_1:0, IGeneral_HIL_Mode:0, PaddingGap16_1:0]
    C_RECORD_INSAltitude_VelDown: value-spec=fields=[AltitudeINSsecinfo:0, DownVelocitysecinfo:0]
    C_RECORD_INSATB: value-spec=fields=[ATB_pitchsecinfo:0, ATB_rollsecinfo:0, ATB_yawsecinfo:0]
    C_RECORD_INSATG: value-spec=fields=[ATG_pitchsecinfo:0, ATG_rollsecinfo:0, ATG_yawsecinfo:0]
    C_RECORD_INSLatitudeInfo: value-spec=fields=LatitudeINSsecinfo:8 x 0
    C_RECORD_INSLongitudeInfo: value-spec=fields=LongitudeINSsecinfo:8 x 0
    C_RECORD_INSLTC_LTG: value-spec=fields=[LTC_xsecinfo:0, LTC_ysecinfo:0, LTC_zsecinfo:0, LTG_xsecinfo:0, LTG_ysecinfo:0, LTG_zsecinfo:0]
    C_RECORD_LACommon: value-spec=fields=[LA_Zero_byte:0, LA_Protocol_Version:0, LA_Sync_ID:0, LA_Num_Of_Lanes_Close_Left:0, LA_Num_Of_Lanes_Close_Right:0, Reserved_1:0, LA_Num_Of_Lanes_Far_Left:0, LA_Num_Of_Lanes_Far_Right:0, LA_Has_Shoulder_Right_Close:0, PaddingGap8_1:0, PaddingGap16_2:0, LA_Shoulder_Right_Width_Close:0, LA_Has_Shoulder_Right_Far:0, PaddingGap8_3:0, PaddingGap16_4:0, LA_Shoulder_Right_Width_Far:0, LA_Header_Buffer:0, PaddingGap8_5:0, PaddingGap16_6:0]
    C_RECORD_Lane_Support_E: value-spec=fields=[{short-label=gstLS_Host_Line, constant=C_ARRAY_2_LS_Host_Line}, {short-label=stLSCommon, constant=C_RECORD_LSCommon}, {short-label=stHeader, constant=C_RECORD_HEADER}, PaddingGap16_1:0, PaddingGap16_2:0, {short-label=gstLS_Adjacent_Line, constant=C_ARRAY_4_LS_Adjacent_Line}]
    C_RECORD_LaneAssignment: value-spec=fields=[LA_Existence_Probability:0, LA_Role:0, LA_View:0, LA_Classification:0, PaddingGap8_1:0, LA_Classification_Probability:0, LA_Oncoming_Probability:0, LA_Preceding_Directions:0, PaddingGap8_2:0, PaddingGap16_3:0, LA_Direction_Probability:0, LA_Buffer:0]
    C_RECORD_LDW_E: value-spec=fields=[LDW_Zero_byte:0, LDW_Protocol_Version:0, LDW_Sync_ID:0, LDW_Line_Valid_Left:0, LDW_Line_Valid_Right:0, Reserved_1:0, LDW_Suppresion_Reason:0, LDW_Time_To_Warning_Left:0, LDW_Time_To_Warning_Right:0, LDW_Warning_Status_Left:0, LDW_Warning_Status_Right:0, Reserved_2:0, PaddingGap8_1:0]
    C_RECORD_LS_Adjacent_Line: value-spec=fields=[Lane_Track_ID:0, Age:0, PaddingGap16_1:0, Existence_Probability:0, Color:0, Prediction_Type:0, Reserved_13:0, PaddingGap8_2:0, View_Range_Start:0, View_Range_End:0, Reserved_14:0, Type_Class:0, DLM_Type:0, DECEL_Type:0, Line_Role:0, PaddingGap8_3:0, PaddingGap16_4:0, Marker_Width:0, Marker_Width_STD:0, Reserved_15:0, PaddingGap8_5:0, PaddingGap16_6:0, Dash_Average_Length:0, Dash_Average_Gap:0, Reserved_16:0, PaddingGap8_7:0, PaddingGap16_8:0, Line_C0:0, Line_C0_STD:0, Reserved_17:0, PaddingGap8_9:0, PaddingGap16_10:0, Estimated_Width:0, Line_C1:0, Line_C1_STD:0, Buffer:0, PaddingGap8_11:0, PaddingGap16_12:0, Line_C2:0, Line_C2_STD:0, Line_C3:0, Line_C3_STD:0]
    C_RECORD_LS_Host_Line: value-spec=fields=[Valid:0, Track_ID:0, Age:0, PaddingGap8_1:0, Existence_Probability:0, Color:0, Prediction_Type:0, Reserved_1:0, Type_Classification:0, DLM_Type:0, DECEL_Type:0, PaddingGap16_2:0, View_Range_Start:0, Reserved_2:0, PaddingGap8_3:0, PaddingGap16_4:0, View_Range_End:0, Crossing:0, PaddingGap8_5:0, PaddingGap16_6:0, Marker_Width:0, Marker_Width_STD:0, Reserved_3:0, PaddingGap8_7:0, PaddingGap16_8:0, Dash_Average_Length:0, Dash_Average_Gap:0, Reserved_4:0, PaddingGap8_9:0, PaddingGap16_10:0, Line_C0:0, Line_C0_STD:0, Reserved_5:0, PaddingGap8_11:0, PaddingGap16_12:0, Estimated_Width:0, Line_C1:0, Line_C1_STD:0, Reserved_6:0, PaddingGap8_13:0, PaddingGap16_14:0, PaddingGap16_15:0, PaddingGap16_16:0, Line_C2:0, Line_C2_STD:0, Line_C3:0, Line_C3_STD:0]
    C_RECORD_LS_Road_Edge: value-spec=fields=[LS_Road_Edge_ID:0, LS_Road_Edge_Age:0, PaddingGap16_1:0, LS_Road_Edge_Exist_Prob:0, LS_Road_Edge_Type:0, LS_Road_Edge_Prediction_Type:0, PaddingGap16_2:0, LS_Road_Edge_Height:0, LS_Road_Edge_View_Range_Start:0, Reserved_1:0, PaddingGap16_3:0, LS_Road_Edge_View_Range_End:0, PaddingGap16_4:0, PaddingGap16_5:0, LS_Road_Edge_Line_C3:0, LS_Road_Edge_Line_C3_STD:0, Reserved_2:0, PaddingGap16_6:0, LS_Road_Edge_Line_C2:0, LS_Road_Edge_Line_C2_STD:0, LS_Road_Edge_Line_C1:0, LS_Road_Edge_Line_C1_STD:0, Reserved_3:0, PaddingGap16_7:0, LS_Road_Edge_Line_C0:0, LS_Road_Edge_Line_C0_STD:0, LS_Road_Edge_Buffer:0, PaddingGap8_8:0, PaddingGap16_9:0, LS_Road_Edge_Height_STD:0, LS_Road_Edge_Host_Side:0, LS_Road_Edge_From_Host_Index:0, PaddingGap16_10:0, PaddingGap16_11:0, PaddingGap16_12:0]
    C_RECORD_LS_Road_Edge_E: value-spec=fields=[{short-label=gstrLS_Road_Edge, constant=C_ARRAY_4_LS_Road_Edge}, {short-label=strRoadEdgeCommon, constant=C_RECORD_RoadEdgeCommon}, {short-label=stHeader, constant=C_RECORD_HEADER}, PaddingGap16_1:0, PaddingGap16_2:0]
    C_RECORD_LSCommon: value-spec=fields=[Zero_byte:0, LS_Protocol_Version:0, LS_Sync_ID:0, LS_Adjacent_Number:0, LS_CA_Is_Construction_Area:0, LS_Header_Buffer_1:0, PaddingGap16_1:0]
    C_RECORD_MeCommon_E: value-spec=fields=[COM_Zero_byte:0, COM_Protocol_Version:0, COM_Sync_Frame_ID:0, PaddingGap8_1:0, PaddingGap16_2:0, PaddingGap16_3:0, COM_Frame_MCU_TS_Start:0, COM_Last_MCU_Sync_TS:0, Reserved_1:0, PaddingGap8_4:0, PaddingGap16_5:0, COM_Last_Clock_Sync_Error:0, COM_EyeQ_Frame_ID:0, COM_Cam_Frame_ID:0, COM_DayTime_Indicator:0, PaddingGap8_6:0, PaddingGap16_7:0, COM_DayTime_Ind_Quality:0, Reserved_2:0, PaddingGap16_8:0, Reserved_3:0, COM_HIL_Mode_Status:0, COM_Exposure_Type:0, PaddingGap16_9:0, {short-label=stHeader, constant=C_RECORD_HEADER}]
    C_RECORD_MeFreeSpace_E: value-spec=fields=[{short-label=stHeader, constant=C_RECORD_HEADER}, {short-label=FSPCommon, constant=C_RECORD_FSPCommon}, PaddingGap16_1:0, PaddingGap16_2:0, {short-label=gstFSPoint, constant=C_ARRAY_120_FSPoint}]
    C_RECORD_MeFreeSpace_E_x: value-spec=fields=[{short-label=stHeader, constant=C_RECORD_HEADER}, {short-label=FSPCommon, constant=C_RECORD_FSPCommon}, PaddingGap16_1:0, PaddingGap16_2:0, {short-label=gstFSPoint, constant=C_ARRAY_24_FSPoint}]
    C_RECORD_MeLaneAssignment: value-spec=fields=[{short-label=stHeader, constant=C_RECORD_HEADER}, {short-label=stLACommon, constant=C_RECORD_LACommon}, {short-label=gstLaneAssignment, constant=C_ARRAY_10_LaneAssignment}]
    C_RECORD_MeLDW_E: value-spec=fields=[LDW_Zero_byte:0, LDW_Protocol_Version:0, LDW_Sync_ID:0, LDW_Line_Valid_Left:0, LDW_Line_Valid_Right:0, Reserved_1:0, PaddingGap16_1:0, LDW_Suppresion_Reason:0, LDW_Time_To_Warning_Left:0, LDW_Time_To_Warning_Right:0, LDW_Warning_Status_Left:0, LDW_Warning_Status_Right:0, Reserved_2:0, PaddingGap8_2:0]
    C_RECORD_MeLS_ADV_E: value-spec=fields=[{short-label=stHeader, constant=C_RECORD_HEADER}, PaddingGap16_1:0, PaddingGap16_2:0, {short-label=stADVCommon, constant=C_RECORD_ADVCommon}, {short-label=gstINTP, constant=C_ARRAY_8_MeLS_ADV_INTP}]
    C_RECORD_MeLS_ADV_INTP: value-spec=fields=[LS_INTP_Type:0, LS_INTP_Is_Start:0, LS_INTP_Is_Valid:0, LS_INTP_Line_Role:0, LS_INTP_Lat_Distance:0, LS_INTP_Long_Distance:0, Reserved_6:0, LS_INTP_Buffer:0]
    C_RECORD_MeObject: value-spec=fields=[OBJ_ID:0, PaddingGap8_1:0, PaddingGap16_2:0, OBJ_Existence_Probability:0, OBJ_Is_Predicted:0, OBJ_Object_Class:0, OBJ_Object_Age:0, OBJ_Width:0, OBJ_Width_STD:0, OBJ_Length:0, OBJ_Length_STD:0, OBJ_Height:0, OBJ_Height_STD:0, OBJ_Absolute_Long_Velocity:0, OBJ_Absolute_Lat_Velocity:0, OBJ_Abs_Lat_Velocity_STD:0, OBJ_Relative_Long_Velocity:0, OBJ_Relative_Long_Velo_STD:0, OBJ_Relative_Lat_Velocity:0, OBJ_Relative_Lat_Velocity_STD:0, OBJ_Absolute_Lat_Acc:0, OBJ_Absolute_Lat_Acc_STD:0, OBJ_Long_Distance:0, OBJ_Long_Distance_STD:0, OBJ_Lat_Distance:0, OBJ_Lat_Distance_STD:0, OBJ_Absolute_Acceleration:0, OBJ_Absolute_Speed:0, OBJ_Motion_Status:0, OBJ_Motion_Category:0, OBJ_Motion_Oreintation:0, PaddingGap8_3:0, OBJ_Heading:0, OBJ_Brake_Light:0, OBJ_Turn_Indicator_Right:0, OBJ_Turn_Indicator_Left:0, OBJ_Light_Indicator_Validity:0, OBJ_Angle_Right:0, OBJ_Angle_Right_STD:0, OBJ_Angle_Left:0, OBJ_Angle_Left_STD:0, OBJ_Angle_Side:0, OBJ_Angle_Mid:0, OBJ_Angle_Mid_STD:0, OBJ_Top_Out_Of_Image:0, OBJ_Bottom_Out_Of_Image:0, OBJ_Right_Out_Of_Image:0, OBJ_Left_Out_Of_Image:0, OBJ_Angle_Rate:0, OBJ_Angle_Rate_STD:0, OBJ_Age_Seconds:0, OBJ_Is_In_Drivable_Area:0, OBJ_Is_VeryClose:0, OBJ_Lane_Assignment:0, OBJ_Camera:0, OBJ_Triggered_SDM:0, OBJ_Measuring_Status:0, OBJ_Lane_Assignment_V:0, OBJ_Top_Out_Of_Image_V:0, OBJ_Bottom_Out_Of_Image_V:0, OBJ_Age_Seconds_V:0, OBJ_Width_V:0, OBJ_Length_V:0, OBJ_Height_V:0, OBJ_Absolute_Long_Velocity_V:0, PaddingGap8_4:0, OBJ_Abs_Long_Velocity_STD:0, OBJ_Absolute_Lat_Velocity_V:0, OBJ_Absolute_Lat_Acc_V:0, OBJ_Absolute_Acceleration_V:0, OBJ_Inv_TTC_V:0, OBJ_Inv_TTC:0, OBJ_Relative_Long_Velocity_V:0, OBJ_Relative_Lat_Velocity_V:0, OBJ_Long_Distance_V:0, OBJ_Lat_Distance_V:0, OBJ_Absolute_Speed_V:0, OBJ_Heading_V:0, PaddingGap16_5:0, OBJ_Absolute_Speed_STD:0, OBJ_Heading_STD:0, OBJ_Angle_Rate_V:0, OBJ_Angle_Right_V:0, OBJ_Angle_Left_V:0, OBJ_Angle_Side_V:0, OBJ_Angle_Side_STD:0, OBJ_Angle_Mid_V:0, OBJ_Is_In_Drivable_Area_V:0, OBJ_Is_VeryClose_V:0, Reserved:14 x 0, PaddingGap8_6:0, PaddingGap16_7:0, OBJ_Absolute_Acce_STD:0]
    C_RECORD_MeObjects_E: value-spec=fields=[{short-label=stHeader, constant=C_RECORD_HEADER}, {short-label=stObjCommon, constant=C_RECORD_ObjCommon}, {short-label=gstMeObject, constant=C_ARRAY_20_MeObject}]
    C_RECORD_MeObjects_E_x: value-spec=fields=[{short-label=stHeader, constant=C_RECORD_HEADER}, {short-label=stObjCommon, constant=C_RECORD_ObjCommon}, {short-label=gstMeObject, constant=C_ARRAY_5_MeObject}]
    C_RECORD_MeSematicLines_E: value-spec=fields=[{short-label=stHeader, constant=C_RECORD_HEADER}, {short-label=stSLCommon, constant=C_RECORD_SLCommon}, {short-label=gstSematicLine, constant=C_ARRAY_10_SematicLine}]
    C_RECORD_MeSematicMark_E: value-spec=fields=[{short-label=stSMCommon, constant=C_RECORD_SMCommon}, {short-label=gstSematicMark, constant=C_ARRAY_20_SematicMark}, {short-label=stHeader, constant=C_RECORD_HEADER}]
    C_RECORD_MeTFL_E: value-spec=fields=[{short-label=gstrTFL, constant=C_ARRAY_10_TFL}, {short-label=strTFLCommon, constant=C_RECORD_TFLCommon}, {short-label=stHeader, constant=C_RECORD_HEADER}]
    C_RECORD_MeTSR_E: value-spec=fields=[{short-label=strTSRCommon, constant=C_RECORD_TSRCommon}, {short-label=gstrTSR, constant=C_ARRAY_20_TSR}, {short-label=stHeader, constant=C_RECORD_HEADER}]
    C_RECORD_MeTSR_E_x: value-spec=fields=[{short-label=strTSRCommon, constant=C_RECORD_TSRCommon}, {short-label=gstrTSR, constant=C_ARRAY_10_TSR}, {short-label=stHeader, constant=C_RECORD_HEADER}]
    C_RECORD_NavStatus_Heading: value-spec=fields=[ChannelInfosecinfo:0, CurrentGPSTimesecinfo:0, Headingsecinfo:0, NavStatussecinfo:0]
    C_RECORD_ObjCommon: value-spec=fields=[OBJ_Zero_byte:0, OBJ_Protocol_Version:0, OBJ_Sync_ID:0, OBJ_VRU_Count:0, OBJ_VD_Count:0, OBJ_General_OBJ_Count:0, OBJ_Animal_Count:0, OBJ_VD_CIPV_ID:0, OBJ_VD_CIPV_Lost:0, OBJ_VD_Allow_Acce:0, OBJ_VD_NIV_Right:0, OBJ_VD_NIV_Left:0, OBJ_Header_Buffer:0]
    C_RECORD_Pitch_Roll: value-spec=fields=[Pitchsecinfo:0, Rollsecinfo:0]
    C_RECORD_PoserrStatus1: value-spec=fields=[AltStdsecinfo:0, LatStdsecinfo:0, LonStdsecinfo:0]
    C_RECORD_RoadEdgeCommon: value-spec=fields=[LS_Road_Edge_Zero_byte:0, LS_Road_Edge_Protocol_Version:0, LS_Road_Edge_Sync_ID:0, LS_Road_Edge_Number:0, LS_Road_Edge_Header_Buffer:0, PaddingGap8_1:0, PaddingGap16_2:0]
    C_RECORD_SematicLine: value-spec=fields=[SL_Long_Dist:0, SL_Long_Dist_STD:0, SL_Probability:0, SL_Is_Relevant:0, PaddingGap8_1:0, PaddingGap16_2:0, SL_Width:0, SL_Length:0, SL_Measure_Status:0, PaddingGap8_3:0, PaddingGap16_4:0, SL_Angle:0, SL_Angle_STD:0, SL_Close_To_Junc:0, PaddingGap8_5:0, PaddingGap16_6:0, SL_Lat_Distance:0, SL_Color:0, SL_Type:0, SL_ID:0, PaddingGap8_7:0]
    C_RECORD_SematicMark: value-spec=fields=[SM_ID:0, PaddingGap8_1:0, PaddingGap16_2:0, SM_Type:0, Reserved_2:0, PaddingGap8_3:0, PaddingGap16_4:0, SM_Lat_Distance:0, SM_Long_Distance:0, SM_Confidence:0, SM_Buffer:0, PaddingGap16_5:0]
    C_RECORD_SL_Descrip_E: value-spec=fields=[{short-label=gstSLD, constant=C_ARRAY_10_SLD}, {short-label=stSLDCommon, constant=C_RECORD_SLDCommon}, {short-label=stHeader, constant=C_RECORD_HEADER}]
    C_RECORD_SLCommon: value-spec=fields=[SL_Zero_byte:0, SL_Protocol_Version:0, SL_Sync_ID:0, SL_Approved_Lines:0, SL_Header_Buffer:0, PaddingGap8_1:0, PaddingGap16_2:0]
    C_RECORD_SLD: value-spec=fields=[SLD_Existence_Probability:0, SLD_NonExistence_Probability:0, SLD_Role:0, SLD_View:0, SLD_Orientation:0, PaddingGap8_1:0, SLD_Orientation_Probability:0, SLD_Direction:0, PaddingGap8_2:0, PaddingGap16_3:0, SLD_Direction_Probability:0, SLD_Type:0, PaddingGap16_4:0, SLD_Type_Probability:0, SLD_Buffer:0, Reserved_2:0, PaddingGap16_5:0]
    C_RECORD_SLDCommon: value-spec=fields=[SLD_Num_Of_Lanes_Far_Left:0, SLD_Num_Of_Lanes_Far_Right:0, SLD_Has_Shoulder_Right_Close:0, PaddingGap8_1:0, SLD_Shoulder_Right_Width_Close:0, SLD_Has_Shoulder_Right_Far:0, PaddingGap8_2:0, PaddingGap16_3:0, SLD_Shoulder_Right_Width_Far:0, SLD_Header_Buffer:0, SLD_Zero_byte:0, SLD_Protocol_Version:0, SLD_Sync_ID:0, SLD_Num_Of_Lanes_Close_Left:0, SLD_Num_Of_Lanes_Close_Right:0, Reserved_1:0, PaddingGap8_4:0]
    C_RECORD_SMCommon: value-spec=fields=[SM_Zero_byte:0, SM_Protocol_Version:0, SM_Sync_ID:0, SM_Header_Buffer:0, SM_Approved_Marks:0, PaddingGap8_1:0, PaddingGap16_2:0]
    C_RECORD_StatusInfo: value-spec=fields=[ECUDelaysecinfo:0, ECUFreqsecinfo:0, GPSDelaysecinfo:0, GPSFreqsecinfo:0, INSDelaysecinfo:0, INSStatussecinfo:0, INSWarningsecinfo:0]
    C_RECORD_TAC2: value-spec=fields=[TAC_Zero_byte:0, TAC_Vision_Protocol_Version:1, TAC_Mode:1, TAC_BottomLeftSquare_0:0, TAC_BottomLeftSquare_1:1, TAC_Targets_Num:3, Reserved_1:0, PaddingGap8_1:0, TAC_TargetInfo_Lat_Distance_0:0.95, TAC_TargetInfo_Lat_Distance_1:0.95, TAC_TargetInfo_Height_0:1.93, TAC_targetInfo_height_1:1.93, TAC_Camera_Height:1.46, TAC_Camera_Z:5.158, TAC_Max_Horizon:0, TAC_Min_Horizon:0, TAC_Max_Yaw:248, TAC_Min_Yaw:0, TAC_Max_RollAngle:0.055, TAC_SquareSideSize:0.155, TAC_Bottom:0, Reserved_2:0, PaddingGap16_2:0]
    C_RECORD_TFL: value-spec=fields=[TFL_Existence_Probability:0, TFL_Relevance_Probability:0, TFL_Color:0, TFL_Mode:0, TFL_Relevance_Direction:0, Reserved_1:0, TFL_Rel_Dir_Quality:0, TFL_Shape:0, TFL_Structure_Orientation:0, PaddingGap16_1:0, TFL_Rel_Height:0, TFL_Rel_Height_STD:0, TFL_Lat_Distance:0, TFL_Lat_Distance_STD:0, TFL_Long_Distance:0, TFL_Long_Distance_STD:0, TFL_Width:0, TFL_Height:0, TFL_Width_STD:0, TFL_Height_STD:0, TFL_Camera_Source:0, TFL_Object_ID:0, TFL_LightBox_ID:0, Reserved_2:0, Reserved_3:0, PaddingGap8_2:0, PaddingGap16_3:0]
    C_RECORD_TFLCommon: value-spec=fields=[TFL_Zero_byte:0, TFL_Protocol_Version:0, TFL_Sync_ID:0, TFL_Number_Of_Objects:0, TFL_Header_Buffer:0, PaddingGap8_1:0, PaddingGap16_2:0]
    C_RECORD_TSR: value-spec=fields=[TSR_ID:0, TSR_Camera_Source:0, PaddingGap16_1:0, TSR_Sign_Name:0, TSR_Relevancy:0, TSR_Filter_Type:0, Reserved_3:0, TSR_Sup1_SignName:0, TSR_Sup1_Confidence:0, TSR_Sup2_SignName:0, PaddingGap8_2:0, PaddingGap16_3:0, TSR_Sup2_Confidence:0, Reserved_4:0, TSR_Sign_Shape:0, TSR_Sign_Structure:0, PaddingGap8_4:0, TSR_Confidence:0, TSR_Sign_Long_Distance:0, Reserved_5:0, TSR_Sign_Lateral_Distance:0, TSR_Sign_Height:0, Reserved_6:0, PaddingGap8_5:0, PaddingGap16_6:0, TSR_Sign_Long_Distance_STD:0, TSR_Sign_Lat_Distance_STD:0, Reserved_7:0, PaddingGap8_7:0, PaddingGap16_8:0, TSR_Sign_Height_STD:0, TSR_Sign_Panel_Width:0, Reserved_8:0, PaddingGap8_9:0, PaddingGap16_10:0, TSR_Sign_Panel_Height:0, TSR_Sign_Panel_Width_STD:0, TSR_Sign_Panel_Height_STD:0, Reserved_9:0, PaddingGap8_11:0, PaddingGap16_12:0, TSR_Tracking_Age:0]
    C_RECORD_TSRCommon: value-spec=fields=[Zero_byte:0, TSR_Protocol_Version:0, TSR_Sync_ID:0, Reserved_1:0, TSR_APR_Sign_Count:0, TSR_Filtered_Sign_Count:0, TSR_UnderTracking_Sign_Count:0, TSR_Header_Buffer:0, PaddingGap8_1:0, PaddingGap16_2:0]
    C_RECORD_VCUStatus_reserved5: value-spec=fields=[Byte9:0, Byte8:0]
    C_RECORD_VCUStatus_reserved6: value-spec=fields=[Byte11:0, Byte10:0]
    C_RECORD_VCUStatus1: value-spec=fields=[DrivemModeStssecinfo:0, DriveModeReqsecinfo:0, EnSpdsecinfo:0, EPSMotOtptToqsecinfo:0, keep1secinfo:0, PtBrkPdlDscrtInptStssecinfo:0, PtBrkPdlDscrtInptStsVsecinfo:0, SCUShiferLvrPossecinfo:0]
    C_RECORD_VCUStatus10: value-spec=fields=[RNonDrvnWhlRotlDistVHSC2:0, RNonDrvnWhlRotlDistPCHSC2:0, RDrvnWhlRotlDistVHSC2:0, RDrvnWhlRotlDistPlsCtrHSC2:0, LDrvnWhlRotlDistVHSC2:0, LNonDrvnWhlRotlDistPCHSC2:0, LNonDrvnWhlRotlDistVHSC2:0, LDrvnWhlRotlDistPlsCtrHSC2:0]
    C_RECORD_VCUStatus2: value-spec=fields=[StrgWhlAngHSC4:0, StrgWhlAngAlvRCHSC4:0, StrgWhlAngExtdPVHSC4:0, StrgWhlAngGrdHSC4:0, StrgWhlAngSnsrCalStsHSC4:0, StrgWhlAngSnsrChksmHSC4:0, StrgWhlAngSnsrFltHSC4:0, StrgWhlAngSnsrInidHSC4:0, StrgWhlAngSnsrMultCapbHSC4:0, StrgWhlAngVHSC4:0]
    C_RECORD_VCUStatus3: value-spec=fields=[SysVol_HSC4:0, EPBAppcnStsHSC4:0, VehSpdAvgVHSC4:0, VehSpdAvgHSC4:0, VSELongtAccVHSC4:0, VSELongtAccHSC4:0, VehDynYawRateVHSC4:0, VehDynYawRateHSC4:0, AirbagDplHSC4:0]
    C_RECORD_VCUStatus4: value-spec=fields=[VehLckngStaHSC4:0, FrtPsngDoorOpenStsHSC4:0, DrvrDoorOpenStsHSC4:0, VehInertiaSwTrigdHSC4:0, BrkPdlDrvrAppdPrsV_HSC4:0, BrkPdlDrvrAppdPrsAlvRC_HSC4:0, BrkPdlDrvrAppdPrs_HSC4:0]
    C_RECORD_VCUStatus5: value-spec=fields=[VehDeceLmtHSC4:0, VehAcceLmtHSC4:0, StrgWhlAngLmtHSC4:0, StrgWhlAngGrdLmtHSC4:0, RdFrictionCoefficientHSC4:0]
    C_RECORD_VCUStatus6: value-spec=fields=[WhlGndVelLDrvnsecinfo:0, WhlGndVelLDrvnVsecinfo:0, WhlGndVelLNonDrvnsecinfo:0, WhlGndVelLNonDrvnVsecinfo:0, WhlGndVelRDrvnsecinfo:0, WhlGndVelRDrvnVsecinfo:0, WhlGndVelRNonDrvnsecinfo:0, WhlGndVelRNonDrvnVsecinfo:0]
    C_RECORD_VCUStatus7: value-spec=fields=[ACInCarTemHSC4:0, FuelLvlPcntVHSC4:0, FuelLvlPcntHSC4:0, AmbtLghtLvlHSC4:0, OtsdAirTemCrValV_HSC4:0, OtsdAirTemCrVal_HSC4:0, BrkLghtsStaHSC4:0, DangerousWrnngLghtStaHSC4:0, DipdBeamLampsStaHSC4:0, FrtFogLampStaHSC4:0, HornStaHSC4:0, LDircnLampsStaHSC4:0, MainBeamLampsStaHSC4:0, RDircnLampsStaHSC4:0, RevsngLghtStaHSC4:0, RrFogLampStaHSC4:0, WidthLampAndTaillightStateHSC4:0, WiperStaHSC4:0, WshrStaHSC4:0]
    C_RECORD_VCUStatus8: value-spec=fields=[TimeDspFmtHSC2:0, SecsOfMinuteHSC2:0, MinuteOfHourHSC2:0, HourOfDayHSC2:0, CalendarYearHSC5:0, CalendarMonthHSC2:0, CalendarDayHSC2:0]
    C_RECORD_VCUStatus9: value-spec=fields=[VCUMainID:0, VCUAddonsID:0, Vehicleplatform:0, VCUstage:0, Projectname:0, Component:0, VehOdoHSC2:0]
    C_RECORD_VCUStatusTest1: value-spec=fields=[Test4:0, Test3:0, Test2:0, Test1:0]
    C_RECORD_VCUStatusTest2: value-spec=fields=[Test8:0, Test7:0, Test6:0, Test5:0]
    C_RECORD_VCUStatusTest3: value-spec=fields=[Test12:0, Test11:0, Test10:0, Test9:0]
    C_RECORD_VCUStatusTest4: value-spec=fields=[Test16:0, Test15:0, Test14:0, Test13:0]
    C_RECORD_VelNorthEast: value-spec=fields=[EastVelocitysecinfo:0, NorthVelocitysecinfo:0]
    C_RECORD_VersionNumber: value-spec=fields=[ARMAPPVersecinfo:0, ARMBLVersecinfo:0, DSPAPPVersecinfo:0, DSPBLVersecinfo:0]
    C_RequestCalibrationStatus: value-spec=0
package /DataTypes
  145 x impl type, all with sw-calibration-access=READ-ONLY, type-emitter=RTE:
    Dt_ARRAY_10_LaneAssignment: category=ARRAY
      element Element: array-size=10, array-size-semantics=FIXED-SIZE, implementation-data-type=Dt_RECORD_LaneAssignment
    Dt_ARRAY_10_SematicLine: category=ARRAY
      element Element: array-size=10, array-size-semantics=FIXED-SIZE, implementation-data-type=Dt_RECORD_SematicLine
    Dt_ARRAY_10_SLD: category=ARRAY
      element Element: array-size=10, array-size-semantics=FIXED-SIZE, implementation-data-type=Dt_RECORD_SLD
    Dt_ARRAY_10_TFL: category=ARRAY
      element Element: array-size=10, array-size-semantics=FIXED-SIZE, implementation-data-type=Dt_RECORD_TFL
    Dt_ARRAY_10_TSR: category=ARRAY
      element Element: array-size=10, array-size-semantics=FIXED-SIZE, implementation-data-type=Dt_RECORD_TSR
    Dt_ARRAY_120_FSPoint: category=ARRAY
      element Element: array-size=120, array-size-semantics=FIXED-SIZE, implementation-data-type=Dt_RECORD_FSPoint
    Dt_ARRAY_14_ConArea: category=ARRAY
      element Element: array-size=14, array-size-semantics=FIXED-SIZE, implementation-data-type=Dt_RECORD_ConArea
    Dt_ARRAY_14_uint8: category=ARRAY
      element Element: array-size=14, array-size-semantics=FIXED-SIZE, implementation-data-type=uint8
    Dt_ARRAY_2_LS_Host_Line: category=ARRAY
      element Element: array-size=2, array-size-semantics=FIXED-SIZE, implementation-data-type=Dt_RECORD_LS_Host_Line
    Dt_ARRAY_20_MeObject: category=ARRAY
      element Element: array-size=20, array-size-semantics=FIXED-SIZE, implementation-data-type=Dt_RECORD_MeObject
    Dt_ARRAY_20_SematicMark: category=ARRAY
      element Element: array-size=20, array-size-semantics=FIXED-SIZE, implementation-data-type=Dt_RECORD_SematicMark
    Dt_ARRAY_20_TSR: category=ARRAY
      element Element: array-size=20, array-size-semantics=FIXED-SIZE, implementation-data-type=Dt_RECORD_TSR
    Dt_ARRAY_24_FSPoint: category=ARRAY
      element Element: array-size=24, array-size-semantics=FIXED-SIZE, implementation-data-type=Dt_RECORD_FSPoint
    Dt_ARRAY_4_LS_Adjacent_Line: category=ARRAY
      element Element: array-size=4, array-size-semantics=FIXED-SIZE, implementation-data-type=Dt_RECORD_LS_Adjacent_Line
    Dt_ARRAY_4_LS_Road_Edge: category=ARRAY
      element Element: array-size=4, array-size-semantics=FIXED-SIZE, implementation-data-type=Dt_RECORD_LS_Road_Edge
    Dt_ARRAY_5_MeObject: category=ARRAY
      element Element: array-size=5, array-size-semantics=FIXED-SIZE, implementation-data-type=Dt_RECORD_MeObject
    Dt_ARRAY_8_GPSLatitudeHSC4: category=ARRAY
      element Element: array-size=8, array-size-semantics=FIXED-SIZE, implementation-data-type=uint8
    Dt_ARRAY_8_GPSLongitudeHSC4: category=ARRAY
      element Element: array-size=8, array-size-semantics=FIXED-SIZE, implementation-data-type=uint8
    Dt_ARRAY_8_LatitudeINSsecinfo: category=ARRAY
      element Element: array-size=8, array-size-semantics=FIXED-SIZE, implementation-data-type=uint8
    Dt_ARRAY_8_LongitudeINSsecinfo: category=ARRAY
      element Element: array-size=8, array-size-semantics=FIXED-SIZE, implementation-data-type=uint8
    Dt_ARRAY_8_MeLS_ADV_INTP: category=ARRAY
      element Element: array-size=8, array-size-semantics=FIXED-SIZE, implementation-data-type=Dt_RECORD_MeLS_ADV_INTP
    Dt_ARRAY_UINT64_1_0: category=ARRAY
      element Element: array-size=2, array-size-semantics=FIXED-SIZE, implementation-data-type=uint32
    Dt_RECORD_AccBias_Lcc: category=STRUCTURE
      4 x element, all with category=TYPE_REFERENCE, implementation-data-type=float32:
        AxBiassecinfo
        AyBiassecinfo
        AzBiassecinfo
        Lccsecinfo
    Dt_RECORD_Acce_AngularVel_X: category=STRUCTURE
      element AccelerationXsecinfo: implementation-data-type=float32
      element AngularRateXsecinfo: implementation-data-type=float32
    Dt_RECORD_Acce_AngularVel_Y: category=STRUCTURE
      element AccelerationYsecinfo: implementation-data-type=float32
      element AngularRateYsecinfo: implementation-data-type=float32
    Dt_RECORD_Acce_AngularVel_Z: category=STRUCTURE
      element AccelerationZsecinfo: implementation-data-type=float32
      element AngularRateZsecinfo: implementation-data-type=float32
    Dt_RECORD_ADVCommon: category=STRUCTURE
      41 x element, all with category=TYPE_REFERENCE:
        LS_ADV_Zero_byte: implementation-data-type=uint8
        LS_ADV_Protocol_Version: implementation-data-type=uint8
        LS_ADV_Sync_ID: implementation-data-type=uint8
        LS_INTP_Number: implementation-data-type=uint8
        LS_CA_Is_Construction_Area: implementation-data-type=boolean
        LS_Road_Vertical_Surface_Valid: implementation-data-type=boolean
        Reserved_1: implementation-data-type=uint8
        LS_Road_Vertical_Surface_VR: implementation-data-type=uint8
        LS_Road_Vertical_Surface_C0: implementation-data-type=float32
        LS_Road_Vertical_Surface_C1: implementation-data-type=float32
        Reserved_2: implementation-data-type=uint8
        PaddingGap8_1: implementation-data-type=uint8
        PaddingGap16_{2..4}: implementation-data-type=uint16
        LS_Road_Vertical_Surface_C2: implementation-data-type=float64
        Reserved_3: implementation-data-type=uint16
        PaddingGap16_{5..7}: implementation-data-type=uint16
        LS_Road_Vertical_Surface_C3: implementation-data-type=float64
        LS_Path_Pred_Valid: implementation-data-type=boolean
        PaddingGap8_8: implementation-data-type=uint8
        PaddingGap16_9: implementation-data-type=uint16
        LS_Path_Pred_C0: implementation-data-type=float32
        Reserved_4: implementation-data-type=uint8
        PaddingGap8_10: implementation-data-type=uint8
        PaddingGap16_11: implementation-data-type=uint16
        LS_Path_Pred_C1: implementation-data-type=float32
        LS_Path_Pred_C2: implementation-data-type=float64
        Reserved_5: implementation-data-type=uint32
        PaddingGap16_12: implementation-data-type=uint16
        PaddingGap16_13: implementation-data-type=uint16
        LS_Path_Pred_C3: implementation-data-type=float64
        LS_Path_Pred_Conf: implementation-data-type=float32
        LS_Path_Pred_Half_Width: implementation-data-type=float32
        LS_INTP_Is_Highway_Merge_Left: implementation-data-type=boolean
        LS_INTP_Is_Highway_Merge_Right: implementation-data-type=boolean
        LS_INTP_Is_Highway_Exit_Left: implementation-data-type=boolean
        LS_INTP_Is_Highway_Exit_Right: implementation-data-type=boolean
        LS_INTP_Header_Buffer: implementation-data-type=uint32
    Dt_RECORD_AtterrStatus2: category=STRUCTURE
      6 x element, all with category=TYPE_REFERENCE, implementation-data-type=float32:
        PitchStdsecinfo
        RollStdsecinfo
        VelDStdsecinfo
        VelEStdsecinfo
        VelNStdsecinfo
        YawStdsecinfo
    Dt_RECORD_CACommon: category=STRUCTURE
      6 x element, all with category=TYPE_REFERENCE:
        CA_Zero_byte: implementation-data-type=uint8
        CA_Protocol_Version: implementation-data-type=uint8
        CA_Sync_ID: implementation-data-type=sint16
        CA_Region_Code: implementation-data-type=uint8
        CA_Objects_Count: implementation-data-type=uint8
        PaddingGap16_1: implementation-data-type=uint16
    Dt_RECORD_CodingEnviroment: category=STRUCTURE
      24 x element, all with category=TYPE_REFERENCE:
        CEnvironment_Zero_byte: implementation-data-type=uint8
        CEnvironment_Protocol_Version: implementation-data-type=uint8
        PaddingGap16_1: implementation-data-type=uint16
        CEnvironment_leftWheel: implementation-data-type=float32
        CEnvironment_rightWheel: implementation-data-type=float32
        CEnvironment_minHorizon_M: implementation-data-type=sint16
        CEnvironment_maxHorizon_M: implementation-data-type=sint16
        CEnvironment_minYaw_M: implementation-data-type=sint16
        CEnvironment_maxYaw_M: implementation-data-type=uint16
        Reserved_1: implementation-data-type=uint8
        PaddingGap8_2: implementation-data-type=uint8
        PaddingGap16_3: implementation-data-type=uint16
        CEnvironment_camToRearAxle: implementation-data-type=float32
        CEnvironment_wheelRadius: implementation-data-type=float32
        Reserved_2: implementation-data-type=uint8
        PaddingGap8_4: implementation-data-type=uint8
        PaddingGap16_5: implementation-data-type=uint16
        CEnvironment_refPX_Front_Bumper: implementation-data-type=float32
        CEnvironment_camToFrontAxle: implementation-data-type=float32
        CEnvironment_wheelWidth: implementation-data-type=float32
        CEnvironment_Max_Roll: implementation-data-type=float32
        Reserved_3: implementation-data-type=uint8
        PaddingGap8_6: implementation-data-type=uint8
        PaddingGap16_7: implementation-data-type=uint16
    Dt_RECORD_ConArea: category=STRUCTURE
      21 x element, all with category=TYPE_REFERENCE:
        CA_ID: implementation-data-type=uint8
        CA_Frame_Age: implementation-data-type=uint8
        CA_CA_Object_Type: implementation-data-type=uint8
        PaddingGap8_1: implementation-data-type=uint8
        CA_Long_Distance: implementation-data-type=float32
        CA_Long_DistancSTD: implementation-data-type=float32
        CA_Lat_Distance: implementation-data-type=float32
        CA_Lat_DistancSTD: implementation-data-type=float32
        CA_Height: implementation-data-type=float32
        CA_Height_STD: implementation-data-type=float32
        CA_Object_Height: implementation-data-type=float32
        CA_Object_Height_STD: implementation-data-type=float32
        CA_Object_Width: implementation-data-type=float32
        CA_Object_Width_STD: implementation-data-type=float32
        CA_Buffer: implementation-data-type=uint8
        PaddingGap8_2: implementation-data-type=uint8
        Reserved_1: implementation-data-type=uint16
        Reserved_{2..4}: implementation-data-type=uint8
        PaddingGap8_3: implementation-data-type=uint8
    Dt_RECORD_ConstructionArea_E: category=STRUCTURE
      element stHeader: implementation-data-type=Dt_RECORD_HEADER
      element stCACommon: implementation-data-type=Dt_RECORD_CACommon
      element gstConArea: implementation-data-type=Dt_ARRAY_14_ConArea
    Dt_RECORD_CurrentMode: category=STRUCTURE
      4 x element, all with category=TYPE_REFERENCE:
        stHeader: implementation-data-type=Dt_RECORD_HEADER
        CurrentMode: implementation-data-type=uint8
        PaddingGap8_1: implementation-data-type=uint8
        PaddingGap16_2: implementation-data-type=uint16
    Dt_RECORD_Diagnosticmessage_IMU: category=STRUCTURE
      4 x element, all with category=TYPE_REFERENCE, implementation-data-type=uint8:
        DiffDataLinkBrokensecinfo
        GNSSAntenasBrokensecinfo
        GPSMsgErrInIMUsecinfo
        IECUMsgErrInIMUsecinfo
    Dt_RECORD_ETC1: category=STRUCTURE
      9 x element, all with category=TYPE_REFERENCE:
        SrcAddressCtrlDeviceForTransCtrl: implementation-data-type=uint8
        TransInputShaftSpeed: implementation-data-type=float32
        ProgressiveShiftDisable: implementation-data-type=uint8
        EngineMomentaryOverspeedEnable: implementation-data-type=uint8
        PercentClutchSlip: implementation-data-type=float32
        TransOutputShaftSpeed: implementation-data-type=float32
        TransShiftlnProcess: implementation-data-type=uint8
        TransTorqueConverterLockupEngag: implementation-data-type=uint8
        TransDrivelineEngaged: implementation-data-type=uint8
    Dt_RECORD_FSPCommon: category=STRUCTURE
      6 x element, all with category=TYPE_REFERENCE:
        FSP_Zero_byte: implementation-data-type=uint8
        FSP_Protocol_Version: implementation-data-type=uint8
        FSP_Sync_ID: implementation-data-type=sint16
        FSP_Num_Of_Obstacles: implementation-data-type=uint8
        Reserved_1: implementation-data-type=boolean
        PaddingGap16_1: implementation-data-type=uint16
    Dt_RECORD_FSPoint: category=STRUCTURE
      21 x element, all with category=TYPE_REFERENCE:
        FSP_ID: implementation-data-type=sint16
        FSP_Is_Valid: implementation-data-type=boolean
        PaddingGap8_1: implementation-data-type=uint8
        FSP_Existence_Prob: implementation-data-type=float32
        FSP_Emptiness_Prob: implementation-data-type=float32
        FSP_Classification_Type: implementation-data-type=uint8
        FSP_Mobility_Status: implementation-data-type=uint8
        PaddingGap16_2: implementation-data-type=uint16
        FSP_Range: implementation-data-type=float32
        Reserved_2: implementation-data-type=uint16
        PaddingGap16_3: implementation-data-type=uint16
        FSP_Range_STD: implementation-data-type=float32
        FSP_Height: implementation-data-type=float32
        FSP_Height_STD: implementation-data-type=float32
        PaddingGap16_4: implementation-data-type=uint16
        PaddingGap16_5: implementation-data-type=uint16
        FSP_Azimuth_Angle: implementation-data-type=float64
        FSP_Buffer: implementation-data-type=uint16
        PaddingGap16_{6..8}: implementation-data-type=uint16
    Dt_RECORD_GPS_ECUStatus: category=STRUCTURE
      8 x element, all with category=TYPE_REFERENCE:
        ECUWarningsecinfo: implementation-data-type=uint8
        GPSHeadingStatussecinfo: implementation-data-type=uint8
        GPSPosStatussecinfo: implementation-data-type=uint8
        GPSStatussecinfo: implementation-data-type=uint16
        GPSVelStatussecinfo: implementation-data-type=uint8
        GPSWarningsecinfo: implementation-data-type=uint8
        RTKDelaysecinfo: implementation-data-type=uint8
        VehiclesStatussecinfo: implementation-data-type=uint8
    Dt_RECORD_GPSPos_HeadingPrecison: category=STRUCTURE
      4 x element, all with category=TYPE_REFERENCE, implementation-data-type=float32:
        AltSigmaGPSsecinfo
        HeadingSigmaGPSsecinfo
        LatSigmaGPSsecinfo
        LonSigmaGPSsecinfo
    Dt_RECORD_GPSVel_PitchPrecison: category=STRUCTURE
      4 x element, all with category=TYPE_REFERENCE, implementation-data-type=float32:
        PitchSigmaGPSsecinfo
        VeldownsigmaGPSsecinfo
        VeleastsigmaGPSsecinfo
        VelnorthsigmaGPSsecinfo
    Dt_RECORD_HEADER: category=STRUCTURE
      4 x element, all with category=TYPE_REFERENCE:
        TimeStamp: implementation-data-type=Dt_ARRAY_UINT64_1_0
        FrameID: implementation-data-type=uint8
        PaddingGap8_1: implementation-data-type=uint8
        Counter: implementation-data-type=uint16
    Dt_RECORD_HLB_E: category=STRUCTURE
      9 x element, all with category=TYPE_REFERENCE:
        HLB_Zero_byte: implementation-data-type=uint8
        HLB_Protocol_Version: implementation-data-type=uint8
        HLB_Sync_ID: implementation-data-type=uint8
        HLB_Running_Mode: implementation-data-type=sint8
        HLB_InActive_Reason: implementation-data-type=uint8
        HLB_Decision: implementation-data-type=uint8
        Reserved_1: implementation-data-type=boolean
        PaddingGap8_1: implementation-data-type=uint8
        HLB_Reason: implementation-data-type=uint32
    Dt_RECORD_IDC: category=STRUCTURE
      23 x element, all with category=TYPE_REFERENCE:
        IDCDTC: implementation-data-type=Dt_RECORD_IDCDTC
        IDCStatus{1..9}: implementation-data-type=Dt_RECORD_IDCStatus{1..9}
        IDCStatus{40..43}: implementation-data-type=Dt_RECORD_IDCStatus{40..43}
        IDCStatus{91..93}: implementation-data-type=Dt_RECORD_IDCStatus{91..93}
        IDCStatus_reserved{1..6}: implementation-data-type=Dt_RECORD_IDCStatus_reserved{1..6}
    Dt_RECORD_IDCDTC: category=STRUCTURE
      4 x element, all with category=TYPE_REFERENCE:
        FailureBitPegsusInternal: implementation-data-type=uint8
        FailureBitODFSPegsus: implementation-data-type=uint32
        FailureBitODFSIECU2: implementation-data-type=uint32
        FailureBitLoc: implementation-data-type=uint32
    Dt_RECORD_IDCStatus_reserved1: category=STRUCTURE
      element Byte_1: implementation-data-type=uint32
      element Byte_0: implementation-data-type=uint32
    Dt_RECORD_IDCStatus_reserved2: category=STRUCTURE
      element Byte_3: implementation-data-type=uint32
      element Byte_2: implementation-data-type=uint32
    Dt_RECORD_IDCStatus_reserved3: category=STRUCTURE
      element Byte_5: implementation-data-type=uint32
      element Byte_4: implementation-data-type=uint32
    Dt_RECORD_IDCStatus_reserved4: category=STRUCTURE
      element Byte_7: implementation-data-type=uint32
      element Byte_6: implementation-data-type=uint32
    Dt_RECORD_IDCStatus_reserved5: category=STRUCTURE
      element Byte_9: implementation-data-type=uint32
      element Byte_8: implementation-data-type=uint32
    Dt_RECORD_IDCStatus_reserved6: category=STRUCTURE
      element Byte_11: implementation-data-type=uint32
      element Byte_10: implementation-data-type=uint32
    Dt_RECORD_IDCStatus1: category=STRUCTURE
      9 x element, all with category=TYPE_REFERENCE:
        RoadFollowErrorHSC4: implementation-data-type=sint8
        StrgWhlAngGrdCmdHSC4: implementation-data-type=float32
        StrgWhlAngCmdVHSC4: implementation-data-type=boolean
        StrgWhlAngCmdHSC4: implementation-data-type=float32
        VehDeceCmdVHSC4: implementation-data-type=boolean
        VehDeceCmdHSC4: implementation-data-type=float32
        EngToqReqVHSC4: implementation-data-type=boolean
        EngToqReqHSC4: implementation-data-type=float32
        IDCReadyHSC4: implementation-data-type=boolean
    Dt_RECORD_IDCStatus2: category=STRUCTURE
      9 x element, all with category=TYPE_REFERENCE:
        Request_Auto: implementation-data-type=boolean
        APP_Status: implementation-data-type=boolean
        APACtlCmd: implementation-data-type=uint8
        VehSpdMaxLmtHSC4: implementation-data-type=float32
        IDCDriveEnvironmentHSC4: implementation-data-type=uint8
        ShifterPosReqHSC4: implementation-data-type=uint8
        VehSpdReqHSC4: implementation-data-type=float32
        ActualYHSC4: implementation-data-type=float32
        ActualXHSC4: implementation-data-type=float32
    Dt_RECORD_IDCStatus3: category=STRUCTURE
      4 x element, all with category=TYPE_REFERENCE:
        YawRateHSC4: implementation-data-type=sint16
        HeadingAngleHSC4: implementation-data-type=float32
        LateralAcceHSC4: implementation-data-type=float32
        LongitudinalAcceHSC4: implementation-data-type=float32
    Dt_RECORD_IDCStatus4: category=STRUCTURE
      5 x element, all with category=TYPE_REFERENCE:
        LongtAccReqHSC4: implementation-data-type=float32
        TrackCoefficiantX2VHSC4: implementation-data-type=boolean
        TrackCoefficiantX2HSC4: implementation-data-type=float32
        TrackCoefficiantX1VHSC4: implementation-data-type=boolean
        TrackCoefficiantX1HSC4: implementation-data-type=float32
    Dt_RECORD_IDCStatus40: category=STRUCTURE
      element TrackCoefficiantX2HSC4_QJ: implementation-data-type=float32
      element TrackCoefficiantX1HSC4_QJ: implementation-data-type=float32
    Dt_RECORD_IDCStatus41: category=STRUCTURE
      element TrackCoefficiantX4HSC4_QJ: implementation-data-type=float32
      element TrackCoefficiantX3HSC4_QJ: implementation-data-type=float32
    Dt_RECORD_IDCStatus42: category=STRUCTURE
      element TrackCoefficiantX5HSC4_QJ: implementation-data-type=float32
      element TrackCoefficiantY2HSC4_QJ: implementation-data-type=float32
      element TrackCoefficiantY1HSC4_QJ: implementation-data-type=float32
    Dt_RECORD_IDCStatus43: category=STRUCTURE
      element TrackCoefficiantY5HSC4_QJ: implementation-data-type=float32
      element TrackCoefficiantY4HSC4_QJ: implementation-data-type=float32
      element TrackCoefficiantY3HSC4_QJ: implementation-data-type=float32
    Dt_RECORD_IDCStatus5: category=STRUCTURE
      5 x element, all with category=TYPE_REFERENCE:
        INSSlopeHSC4: implementation-data-type=float32
        TrackCoefficiantX4VHSC4: implementation-data-type=boolean
        TrackCoefficiantX4HSC4: implementation-data-type=float32
        TrackCoefficiantX3HSC4: implementation-data-type=float32
        TrackCoefficiantX3VHSC4: implementation-data-type=boolean
    Dt_RECORD_IDCStatus6: category=STRUCTURE
      6 x element, all with category=TYPE_REFERENCE:
        TrackCoefficiantX5VHSC4: implementation-data-type=boolean
        TrackCoefficiantX5HSC4: implementation-data-type=float32
        TrackCoefficiantY2VHSC4: implementation-data-type=boolean
        TrackCoefficiantY2HSC4: implementation-data-type=float32
        TrackCoefficiantY1VHSC4: implementation-data-type=boolean
        TrackCoefficiantY1HSC4: implementation-data-type=float32
    Dt_RECORD_IDCStatus7: category=STRUCTURE
      6 x element, all with category=TYPE_REFERENCE:
        TrackCoefficiantY5HSC4: implementation-data-type=float32
        TrackCoefficiantY5VHSC4: implementation-data-type=boolean
        TrackCoefficiantY4VHSC4: implementation-data-type=boolean
        TrackCoefficiantY4HSC4: implementation-data-type=float32
        TrackCoefficiantY3VHSC4: implementation-data-type=boolean
        TrackCoefficiantY3HSC4: implementation-data-type=float32
    Dt_RECORD_IDCStatus8: category=STRUCTURE
      16 x element, all with category=TYPE_REFERENCE:
        DistanceToStop: implementation-data-type=float32
        Parmtrobg2HSC4: implementation-data-type=float32
        Parmtrobg1HSC4: implementation-data-type=float32
        BrkLghtsCmdHSC4: implementation-data-type=boolean
        DangerousWrnngLghtCmdHSC4: implementation-data-type=boolean
        DipdBeamLampsCmdHSC4: implementation-data-type=boolean
        FrtFogLampCmdHSC4: implementation-data-type=boolean
        HornCmdHSC4: implementation-data-type=boolean
        LDircnLampsCmdHSC4: implementation-data-type=boolean
        MainBeamLampsCmdHSC4: implementation-data-type=boolean
        RDircnLampsCmdHSC4: implementation-data-type=boolean
        RevsngLghtCmdHSC4: implementation-data-type=boolean
        RrFogLampCmdHSC4: implementation-data-type=boolean
        WidthLmpTaillightCmdHSC4: implementation-data-type=boolean
        WiperCmdHSC4: implementation-data-type=uint8
        WshrCmdHSC4: implementation-data-type=boolean
    Dt_RECORD_IDCStatus9: category=STRUCTURE
      element GPSAngleHSC4: implementation-data-type=float32
    Dt_RECORD_IDCStatus91: category=STRUCTURE
      element GPSLatitudeHSC4: implementation-data-type=Dt_ARRAY_8_GPSLatitudeHSC4
    Dt_RECORD_IDCStatus92: category=STRUCTURE
      element GPSLongitudeHSC4: implementation-data-type=Dt_ARRAY_8_GPSLongitudeHSC4
    Dt_RECORD_IDCStatus93: category=STRUCTURE
      6 x element, all with category=TYPE_REFERENCE:
        RounterChangeHSC4: implementation-data-type=boolean
        PathRadiumAvgHSC4: implementation-data-type=uint16
        IDCAlvRCHSC4: implementation-data-type=uint8
        CurveValidHSC4: implementation-data-type=boolean
        PathRadiumMinHSC4: implementation-data-type=uint16
        PredictedLengthHSC4: implementation-data-type=float32
    Dt_RECORD_iECU_250h: category=STRUCTURE
      element SA_AngleValue: implementation-data-type=float32
    Dt_RECORD_iECU_255h: category=STRUCTURE
      4 x element, all with category=TYPE_REFERENCE:
        iECU_PEGSUS_pilotWarning: implementation-data-type=uint8
        iECU_PEGSUS_pilotStatus: implementation-data-type=uint8
        iECU_pilotDisableInfo: implementation-data-type=uint32
        iECU_pilot_OverrideIndicator: implementation-data-type=boolean
    Dt_RECORD_iECU_256h: category=STRUCTURE
      element iECU_pilot_Steer_Override: implementation-data-type=boolean
    Dt_RECORD_iECU_25Ah: category=STRUCTURE
      element iECU_PEGSUS_AEBState: implementation-data-type=uint8
    Dt_RECORD_IECU_25Bh: category=STRUCTURE
      element LockandTwistSwitch: implementation-data-type=boolean
    Dt_RECORD_IECU_FMS1: category=STRUCTURE
      element HighResolutionTripDistance_FMS: implementation-data-type=uint32
      element HghRsolTotalVehDistance_FMS: implementation-data-type=uint32
    Dt_RECORD_IECU_FMS2: category=STRUCTURE
      element Byte7: implementation-data-type=uint32
      element ResidualLiquidLevel_FMS: implementation-data-type=uint16
    Dt_RECORD_IECU1toPegasus: category=STRUCTURE
      element FailureBitODFSIECU1: implementation-data-type=uint32
      element FailureBitActor01: implementation-data-type=uint32
    Dt_RECORD_IECUInternal: category=STRUCTURE
      element Byte3: implementation-data-type=uint32
      element FailureBitIECU1Internal: implementation-data-type=uint32
    Dt_RECORD_IintISPCCoreVision: category=STRUCTURE
      7 x element, all with category=TYPE_REFERENCE:
        ISPC_Zero_byte: implementation-data-type=uint8
        ISPC_Protocol_Version: implementation-data-type=uint8
        Reserved_1: implementation-data-type=uint8
        IVISION_Protocol_Version: implementation-data-type=uint8
        IVISION_Zero_byte: implementation-data-type=uint8
        Reserved_2: implementation-data-type=uint8
        PaddingGap16_1: implementation-data-type=uint16
    Dt_RECORD_InertialNavigation: category=STRUCTURE
      12 x element, all with category=TYPE_REFERENCE:
        Acce_AngularVel_X: implementation-data-type=Dt_RECORD_Acce_AngularVel_X
        Acce_AngularVel_Y: implementation-data-type=Dt_RECORD_Acce_AngularVel_Y
        Acce_AngularVel_Z: implementation-data-type=Dt_RECORD_Acce_AngularVel_Z
        AtterrStatus2: implementation-data-type=Dt_RECORD_AtterrStatus2
        INSAltitude_VelDown: implementation-data-type=Dt_RECORD_INSAltitude_VelDown
        INSLatitudeInfo: implementation-data-type=Dt_RECORD_INSLatitudeInfo
        INSLongitudeInfo: implementation-data-type=Dt_RECORD_INSLongitudeInfo
        NavStatus_Heading: implementation-data-type=Dt_RECORD_NavStatus_Heading
        Pitch_Roll: implementation-data-type=Dt_RECORD_Pitch_Roll
        PoserrStatus1: implementation-data-type=Dt_RECORD_PoserrStatus1
        StatusInfo: implementation-data-type=Dt_RECORD_StatusInfo
        VelNorthEast: implementation-data-type=Dt_RECORD_VelNorthEast
    Dt_RECORD_InitEnvironment: category=STRUCTURE
      21 x element, all with category=TYPE_REFERENCE:
        IEnvironment_Zero_byte: implementation-data-type=uint8
        IEnvironment_General_Version: implementation-data-type=uint8
        PaddingGap16_1: implementation-data-type=uint16
        IEnvironment_leftWheel: implementation-data-type=float32
        IEnvironment_rightWheel: implementation-data-type=float32
        IEnvironment_refPX_Front_Bumper: implementation-data-type=float32
        IEnvironment_camToFrontAxle: implementation-data-type=float32
        IEnvironment_camToRearAxle: implementation-data-type=float32
        IEnvironment_wheelWidth: implementation-data-type=float32
        IEnvironment_wheelRadius: implementation-data-type=float32
        IEnvironment_minHorizon_M: implementation-data-type=sint16
        IEnvironment_maxHorizon_M: implementation-data-type=sint16
        IEnvironment_minYaw_M: implementation-data-type=sint16
        IEnvironment_maxYaw_M: implementation-data-type=uint16
        Reserved_1: implementation-data-type=uint8
        Reserved_2: implementation-data-type=uint8
        PaddingGap16_2: implementation-data-type=uint16
        IEnvironment_Max_Roll: implementation-data-type=float32
        Reserved_3: implementation-data-type=uint8
        PaddingGap8_3: implementation-data-type=uint8
        PaddingGap16_4: implementation-data-type=uint16
    Dt_RECORD_InitGENERAL: category=STRUCTURE
      11 x element, all with category=TYPE_REFERENCE:
        IGeneral_Zero_byte: implementation-data-type=uint8
        IGeneral_Vision_Protocol_Version: implementation-data-type=uint8
        IGeneral_Region_Code: implementation-data-type=uint8
        IGeneral_Driving_Side: implementation-data-type=uint8
        IGeneral_Pitch: implementation-data-type=sint16
        IGeneral_Yaw: implementation-data-type=sint16
        IGeneral_Roll_Angle: implementation-data-type=float32
        IGeneral_Cam_Height: implementation-data-type=float32
        Reserved_1: implementation-data-type=uint8
        IGeneral_HIL_Mode: implementation-data-type=boolean
        PaddingGap16_1: implementation-data-type=uint16
    Dt_RECORD_INSAltitude_VelDown: category=STRUCTURE
      element AltitudeINSsecinfo: implementation-data-type=float32
      element DownVelocitysecinfo: implementation-data-type=float32
    Dt_RECORD_INSATB: category=STRUCTURE
      element ATB_pitchsecinfo: implementation-data-type=float32
      element ATB_rollsecinfo: implementation-data-type=float32
      element ATB_yawsecinfo: implementation-data-type=float32
    Dt_RECORD_INSATG: category=STRUCTURE
      element ATG_pitchsecinfo: implementation-data-type=float32
      element ATG_rollsecinfo: implementation-data-type=float32
      element ATG_yawsecinfo: implementation-data-type=float32
    Dt_RECORD_INSLatitudeInfo: category=STRUCTURE
      element LatitudeINSsecinfo: implementation-data-type=Dt_ARRAY_8_LatitudeINSsecinfo
    Dt_RECORD_INSLongitudeInfo: category=STRUCTURE
      element LongitudeINSsecinfo: implementation-data-type=Dt_ARRAY_8_LongitudeINSsecinfo
    Dt_RECORD_INSLTC_LTG: category=STRUCTURE
      6 x element, all with category=TYPE_REFERENCE, implementation-data-type=float32:
        LTC_xsecinfo
        LTC_ysecinfo
        LTC_zsecinfo
        LTG_xsecinfo
        LTG_ysecinfo
        LTG_zsecinfo
    Dt_RECORD_LACommon: category=STRUCTURE
      19 x element, all with category=TYPE_REFERENCE:
        LA_Zero_byte: implementation-data-type=uint8
        LA_Protocol_Version: implementation-data-type=uint8
        LA_Sync_ID: implementation-data-type=uint8
        LA_Num_Of_Lanes_Close_Left: implementation-data-type=uint8
        LA_Num_Of_Lanes_Close_Right: implementation-data-type=uint8
        Reserved_1: implementation-data-type=uint8
        LA_Num_Of_Lanes_Far_Left: implementation-data-type=uint8
        LA_Num_Of_Lanes_Far_Right: implementation-data-type=uint8
        LA_Has_Shoulder_Right_Close: implementation-data-type=boolean
        PaddingGap8_1: implementation-data-type=uint8
        PaddingGap16_2: implementation-data-type=uint16
        LA_Shoulder_Right_Width_Close: implementation-data-type=float32
        LA_Has_Shoulder_Right_Far: implementation-data-type=boolean
        PaddingGap8_3: implementation-data-type=uint8
        PaddingGap16_4: implementation-data-type=uint16
        LA_Shoulder_Right_Width_Far: implementation-data-type=float32
        LA_Header_Buffer: implementation-data-type=uint8
        PaddingGap8_5: implementation-data-type=uint8
        PaddingGap16_6: implementation-data-type=uint16
    Dt_RECORD_Lane_Support_E: category=STRUCTURE
      6 x element, all with category=TYPE_REFERENCE:
        gstLS_Host_Line: implementation-data-type=Dt_ARRAY_2_LS_Host_Line
        stLSCommon: implementation-data-type=Dt_RECORD_LSCommon
        stHeader: implementation-data-type=Dt_RECORD_HEADER
        PaddingGap16_1: implementation-data-type=uint16
        PaddingGap16_2: implementation-data-type=uint16
        gstLS_Adjacent_Line: implementation-data-type=Dt_ARRAY_4_LS_Adjacent_Line
    Dt_RECORD_LaneAssignment: category=STRUCTURE
      12 x element, all with category=TYPE_REFERENCE:
        LA_Existence_Probability: implementation-data-type=float32
        LA_Role: implementation-data-type=uint8
        LA_View: implementation-data-type=uint8
        LA_Classification: implementation-data-type=uint8
        PaddingGap8_1: implementation-data-type=uint8
        LA_Classification_Probability: implementation-data-type=float32
        LA_Oncoming_Probability: implementation-data-type=float32
        LA_Preceding_Directions: implementation-data-type=uint8
        PaddingGap8_2: implementation-data-type=uint8
        PaddingGap16_3: implementation-data-type=uint16
        LA_Direction_Probability: implementation-data-type=float32
        LA_Buffer: implementation-data-type=float32
    Dt_RECORD_LDW_E: category=STRUCTURE
      13 x element, all with category=TYPE_REFERENCE:
        LDW_Zero_byte: implementation-data-type=uint8
        LDW_Protocol_Version: implementation-data-type=uint8
        LDW_Sync_ID: implementation-data-type=uint8
        LDW_Line_Valid_Left: implementation-data-type=boolean
        LDW_Line_Valid_Right: implementation-data-type=boolean
        Reserved_1: implementation-data-type=uint8
        LDW_Suppresion_Reason: implementation-data-type=uint16
        LDW_Time_To_Warning_Left: implementation-data-type=float32
        LDW_Time_To_Warning_Right: implementation-data-type=float32
        LDW_Warning_Status_Left: implementation-data-type=uint8
        LDW_Warning_Status_Right: implementation-data-type=uint8
        Reserved_2: implementation-data-type=uint8
        PaddingGap8_1: implementation-data-type=uint8
    Dt_RECORD_LS_Adjacent_Line: category=STRUCTURE
      42 x element, all with category=TYPE_REFERENCE:
        Lane_Track_ID: implementation-data-type=uint8
        Age: implementation-data-type=uint8
        PaddingGap16_1: implementation-data-type=uint16
        Existence_Probability: implementation-data-type=float32
        Color: implementation-data-type=uint8
        Prediction_Type: implementation-data-type=uint8
        Reserved_13: implementation-data-type=uint8
        PaddingGap8_2: implementation-data-type=uint8
        View_Range_Start: implementation-data-type=float32
        View_Range_End: implementation-data-type=float32
        Reserved_14: implementation-data-type=uint8
        Type_Class: implementation-data-type=uint8
        DLM_Type: implementation-data-type=uint8
        DECEL_Type: implementation-data-type=uint8
        Line_Role: implementation-data-type=uint8
        PaddingGap8_3: implementation-data-type=uint8
        PaddingGap16_4: implementation-data-type=uint16
        Marker_Width: implementation-data-type=float32
        Marker_Width_STD: implementation-data-type=float32
        Reserved_15: implementation-data-type=uint8
        PaddingGap8_5: implementation-data-type=uint8
        PaddingGap16_6: implementation-data-type=uint16
        Dash_Average_Length: implementation-data-type=float32
        Dash_Average_Gap: implementation-data-type=float32
        Reserved_16: implementation-data-type=uint8
        PaddingGap8_7: implementation-data-type=uint8
        PaddingGap16_8: implementation-data-type=uint16
        Line_C0: implementation-data-type=float32
        Line_C0_STD: implementation-data-type=float32
        Reserved_17: implementation-data-type=uint8
        PaddingGap8_9: implementation-data-type=uint8
        PaddingGap16_10: implementation-data-type=uint16
        Estimated_Width: implementation-data-type=float32
        Line_C1: implementation-data-type=float32
        Line_C1_STD: implementation-data-type=float32
        Buffer: implementation-data-type=uint8
        PaddingGap8_11: implementation-data-type=uint8
        PaddingGap16_12: implementation-data-type=uint16
        Line_C2: implementation-data-type=float64
        Line_C2_STD: implementation-data-type=float64
        Line_C3: implementation-data-type=float64
        Line_C3_STD: implementation-data-type=float64
    Dt_RECORD_LS_Host_Line: category=STRUCTURE
      47 x element, all with category=TYPE_REFERENCE:
        Valid: implementation-data-type=boolean
        Track_ID: implementation-data-type=uint8
        Age: implementation-data-type=uint8
        PaddingGap8_1: implementation-data-type=uint8
        Existence_Probability: implementation-data-type=float32
        Color: implementation-data-type=uint8
        Prediction_Type: implementation-data-type=uint8
        Reserved_1: implementation-data-type=boolean
        Type_Classification: implementation-data-type=uint8
        DLM_Type: implementation-data-type=uint8
        DECEL_Type: implementation-data-type=uint8
        PaddingGap16_2: implementation-data-type=uint16
        View_Range_Start: implementation-data-type=float32
        Reserved_2: implementation-data-type=uint8
        PaddingGap8_3: implementation-data-type=uint8
        PaddingGap16_4: implementation-data-type=uint16
        View_Range_End: implementation-data-type=float32
        Crossing: implementation-data-type=boolean
        PaddingGap8_5: implementation-data-type=uint8
        PaddingGap16_6: implementation-data-type=uint16
        Marker_Width: implementation-data-type=float32
        Marker_Width_STD: implementation-data-type=float32
        Reserved_3: implementation-data-type=boolean
        PaddingGap8_7: implementation-data-type=uint8
        PaddingGap16_8: implementation-data-type=uint16
        Dash_Average_Length: implementation-data-type=float32
        Dash_Average_Gap: implementation-data-type=float32
        Reserved_4: implementation-data-type=uint8
        PaddingGap8_9: implementation-data-type=uint8
        PaddingGap16_10: implementation-data-type=uint16
        Line_C0: implementation-data-type=float32
        Line_C0_STD: implementation-data-type=float32
        Reserved_5: implementation-data-type=uint8
        PaddingGap8_11: implementation-data-type=uint8
        PaddingGap16_12: implementation-data-type=uint16
        Estimated_Width: implementation-data-type=float32
        Line_C1: implementation-data-type=float32
        Line_C1_STD: implementation-data-type=float32
        Reserved_6: implementation-data-type=boolean
        PaddingGap8_13: implementation-data-type=uint8
        PaddingGap16_{14..16}: implementation-data-type=uint16
        Line_C2: implementation-data-type=float64
        Line_C2_STD: implementation-data-type=float64
        Line_C3: implementation-data-type=float64
        Line_C3_STD: implementation-data-type=float64
    Dt_RECORD_LS_Road_Edge: category=STRUCTURE
      35 x element, all with category=TYPE_REFERENCE:
        LS_Road_Edge_ID: implementation-data-type=uint8
        LS_Road_Edge_Age: implementation-data-type=uint8
        PaddingGap16_1: implementation-data-type=uint16
        LS_Road_Edge_Exist_Prob: implementation-data-type=float32
        LS_Road_Edge_Type: implementation-data-type=uint8
        LS_Road_Edge_Prediction_Type: implementation-data-type=uint8
        PaddingGap16_2: implementation-data-type=uint16
        LS_Road_Edge_Height: implementation-data-type=float32
        LS_Road_Edge_View_Range_Start: implementation-data-type=float32
        Reserved_1: implementation-data-type=uint16
        PaddingGap16_3: implementation-data-type=uint16
        LS_Road_Edge_View_Range_End: implementation-data-type=float32
        PaddingGap16_4: implementation-data-type=uint16
        PaddingGap16_5: implementation-data-type=uint16
        LS_Road_Edge_Line_C3: implementation-data-type=float64
        LS_Road_Edge_Line_C3_STD: implementation-data-type=float32
        Reserved_2: implementation-data-type=uint16
        PaddingGap16_6: implementation-data-type=uint16
        LS_Road_Edge_Line_C2: implementation-data-type=float64
        LS_Road_Edge_Line_C2_STD: implementation-data-type=float32
        LS_Road_Edge_Line_C1: implementation-data-type=float32
        LS_Road_Edge_Line_C1_STD: implementation-data-type=float32
        Reserved_3: implementation-data-type=uint16
        PaddingGap16_7: implementation-data-type=uint16
        LS_Road_Edge_Line_C0: implementation-data-type=float32
        LS_Road_Edge_Line_C0_STD: implementation-data-type=float32
        LS_Road_Edge_Buffer: implementation-data-type=uint8
        PaddingGap8_8: implementation-data-type=uint8
        PaddingGap16_9: implementation-data-type=uint16
        LS_Road_Edge_Height_STD: implementation-data-type=float32
        LS_Road_Edge_Host_Side: implementation-data-type=uint8
        LS_Road_Edge_From_Host_Index: implementation-data-type=uint8
        PaddingGap16_{10..12}: implementation-data-type=uint16
    Dt_RECORD_LS_Road_Edge_E: category=STRUCTURE
      5 x element, all with category=TYPE_REFERENCE:
        gstrLS_Road_Edge: implementation-data-type=Dt_ARRAY_4_LS_Road_Edge
        strRoadEdgeCommon: implementation-data-type=Dt_RECORD_RoadEdgeCommon
        stHeader: implementation-data-type=Dt_RECORD_HEADER
        PaddingGap16_1: implementation-data-type=uint16
        PaddingGap16_2: implementation-data-type=uint16
    Dt_RECORD_LSCommon: category=STRUCTURE
      7 x element, all with category=TYPE_REFERENCE:
        Zero_byte: implementation-data-type=uint8
        LS_Protocol_Version: implementation-data-type=uint8
        LS_Sync_ID: implementation-data-type=uint8
        LS_Adjacent_Number: implementation-data-type=uint8
        LS_CA_Is_Construction_Area: implementation-data-type=boolean
        LS_Header_Buffer_1: implementation-data-type=uint8
        PaddingGap16_1: implementation-data-type=uint16
    Dt_RECORD_MeCommon_E: category=STRUCTURE
      25 x element, all with category=TYPE_REFERENCE:
        COM_Zero_byte: implementation-data-type=uint8
        COM_Protocol_Version: implementation-data-type=uint8
        COM_Sync_Frame_ID: implementation-data-type=uint8
        PaddingGap8_1: implementation-data-type=uint8
        PaddingGap16_2: implementation-data-type=uint16
        PaddingGap16_3: implementation-data-type=uint16
        COM_Frame_MCU_TS_Start: implementation-data-type=uint64
        COM_Last_MCU_Sync_TS: implementation-data-type=uint64
        Reserved_1: implementation-data-type=uint8
        PaddingGap8_4: implementation-data-type=uint8
        PaddingGap16_5: implementation-data-type=uint16
        COM_Last_Clock_Sync_Error: implementation-data-type=sint32
        COM_EyeQ_Frame_ID: implementation-data-type=uint32
        COM_Cam_Frame_ID: implementation-data-type=uint32
        COM_DayTime_Indicator: implementation-data-type=uint8
        PaddingGap8_6: implementation-data-type=uint8
        PaddingGap16_7: implementation-data-type=uint16
        COM_DayTime_Ind_Quality: implementation-data-type=float32
        Reserved_2: implementation-data-type=uint16
        PaddingGap16_8: implementation-data-type=uint16
        Reserved_3: implementation-data-type=uint32
        COM_HIL_Mode_Status: implementation-data-type=boolean
        COM_Exposure_Type: implementation-data-type=uint8
        PaddingGap16_9: implementation-data-type=uint16
        stHeader: implementation-data-type=Dt_RECORD_HEADER
    Dt_RECORD_MeFreeSpace_E: category=STRUCTURE
      5 x element, all with category=TYPE_REFERENCE:
        stHeader: implementation-data-type=Dt_RECORD_HEADER
        FSPCommon: implementation-data-type=Dt_RECORD_FSPCommon
        PaddingGap16_1: implementation-data-type=uint16
        PaddingGap16_2: implementation-data-type=uint16
        gstFSPoint: implementation-data-type=Dt_ARRAY_120_FSPoint
    Dt_RECORD_MeFreeSpace_E_x: category=STRUCTURE
      5 x element, all with category=TYPE_REFERENCE:
        stHeader: implementation-data-type=Dt_RECORD_HEADER
        FSPCommon: implementation-data-type=Dt_RECORD_FSPCommon
        PaddingGap16_1: implementation-data-type=uint16
        PaddingGap16_2: implementation-data-type=uint16
        gstFSPoint: implementation-data-type=Dt_ARRAY_24_FSPoint
    Dt_RECORD_MeLaneAssignment: category=STRUCTURE
      element stHeader: implementation-data-type=Dt_RECORD_HEADER
      element stLACommon: implementation-data-type=Dt_RECORD_LACommon
      element gstLaneAssignment: implementation-data-type=Dt_ARRAY_10_LaneAssignment
    Dt_RECORD_MeLDW_E: category=STRUCTURE
      14 x element, all with category=TYPE_REFERENCE:
        LDW_Zero_byte: implementation-data-type=uint8
        LDW_Protocol_Version: implementation-data-type=uint8
        LDW_Sync_ID: implementation-data-type=uint8
        LDW_Line_Valid_Left: implementation-data-type=boolean
        LDW_Line_Valid_Right: implementation-data-type=boolean
        Reserved_1: implementation-data-type=uint8
        PaddingGap16_1: implementation-data-type=uint16
        LDW_Suppresion_Reason: implementation-data-type=float32
        LDW_Time_To_Warning_Left: implementation-data-type=float32
        LDW_Time_To_Warning_Right: implementation-data-type=float32
        LDW_Warning_Status_Left: implementation-data-type=uint8
        LDW_Warning_Status_Right: implementation-data-type=uint8
        Reserved_2: implementation-data-type=uint8
        PaddingGap8_2: implementation-data-type=uint8
    Dt_RECORD_MeLS_ADV_E: category=STRUCTURE
      5 x element, all with category=TYPE_REFERENCE:
        stHeader: implementation-data-type=Dt_RECORD_HEADER
        PaddingGap16_1: implementation-data-type=uint16
        PaddingGap16_2: implementation-data-type=uint16
        stADVCommon: implementation-data-type=Dt_RECORD_ADVCommon
        gstINTP: implementation-data-type=Dt_ARRAY_8_MeLS_ADV_INTP
    Dt_RECORD_MeLS_ADV_INTP: category=STRUCTURE
      8 x element, all with category=TYPE_REFERENCE:
        LS_INTP_Type: implementation-data-type=boolean
        LS_INTP_Is_Start: implementation-data-type=boolean
        LS_INTP_Is_Valid: implementation-data-type=boolean
        LS_INTP_Line_Role: implementation-data-type=uint8
        LS_INTP_Lat_Distance: implementation-data-type=float32
        LS_INTP_Long_Distance: implementation-data-type=float32
        Reserved_6: implementation-data-type=uint16
        LS_INTP_Buffer: implementation-data-type=uint16
    Dt_RECORD_MeObject: category=STRUCTURE
      93 x element, all with category=TYPE_REFERENCE:
        OBJ_ID: implementation-data-type=uint8
        PaddingGap8_1: implementation-data-type=uint8
        PaddingGap16_2: implementation-data-type=uint16
        OBJ_Existence_Probability: implementation-data-type=float32
        OBJ_Is_Predicted: implementation-data-type=uint8
        OBJ_Object_Class: implementation-data-type=uint8
        OBJ_Object_Age: implementation-data-type=uint16
        OBJ_Width: implementation-data-type=float32
        OBJ_Width_STD: implementation-data-type=float32
        OBJ_Length: implementation-data-type=float32
        OBJ_Length_STD: implementation-data-type=float32
        OBJ_Height: implementation-data-type=float32
        OBJ_Height_STD: implementation-data-type=float32
        OBJ_Absolute_Long_Velocity: implementation-data-type=float32
        OBJ_Absolute_Lat_Velocity: implementation-data-type=float32
        OBJ_Abs_Lat_Velocity_STD: implementation-data-type=float32
        OBJ_Relative_Long_Velocity: implementation-data-type=float32
        OBJ_Relative_Long_Velo_STD: implementation-data-type=float32
        OBJ_Relative_Lat_Velocity: implementation-data-type=float32
        OBJ_Relative_Lat_Velocity_STD: implementation-data-type=float32
        OBJ_Absolute_Lat_Acc: implementation-data-type=float32
        OBJ_Absolute_Lat_Acc_STD: implementation-data-type=float32
        OBJ_Long_Distance: implementation-data-type=float32
        OBJ_Long_Distance_STD: implementation-data-type=float32
        OBJ_Lat_Distance: implementation-data-type=float32
        OBJ_Lat_Distance_STD: implementation-data-type=float32
        OBJ_Absolute_Acceleration: implementation-data-type=float32
        OBJ_Absolute_Speed: implementation-data-type=float32
        OBJ_Motion_Status: implementation-data-type=uint8
        OBJ_Motion_Category: implementation-data-type=uint8
        OBJ_Motion_Oreintation: implementation-data-type=uint8
        PaddingGap8_3: implementation-data-type=uint8
        OBJ_Heading: implementation-data-type=float32
        OBJ_Brake_Light: implementation-data-type=boolean
        OBJ_Turn_Indicator_Right: implementation-data-type=boolean
        OBJ_Turn_Indicator_Left: implementation-data-type=boolean
        OBJ_Light_Indicator_Validity: implementation-data-type=boolean
        OBJ_Angle_Right: implementation-data-type=float32
        OBJ_Angle_Right_STD: implementation-data-type=float32
        OBJ_Angle_Left: implementation-data-type=float32
        OBJ_Angle_Left_STD: implementation-data-type=float32
        OBJ_Angle_Side: implementation-data-type=float32
        OBJ_Angle_Mid: implementation-data-type=float32
        OBJ_Angle_Mid_STD: implementation-data-type=float32
        OBJ_Top_Out_Of_Image: implementation-data-type=boolean
        OBJ_Bottom_Out_Of_Image: implementation-data-type=boolean
        OBJ_Right_Out_Of_Image: implementation-data-type=boolean
        OBJ_Left_Out_Of_Image: implementation-data-type=boolean
        OBJ_Angle_Rate: implementation-data-type=float32
        OBJ_Angle_Rate_STD: implementation-data-type=float32
        OBJ_Age_Seconds: implementation-data-type=boolean
        OBJ_Is_In_Drivable_Area: implementation-data-type=boolean
        OBJ_Is_VeryClose: implementation-data-type=boolean
        OBJ_Lane_Assignment: implementation-data-type=uint8
        OBJ_Camera: implementation-data-type=uint8
        OBJ_Triggered_SDM: implementation-data-type=boolean
        OBJ_Measuring_Status: implementation-data-type=uint8
        OBJ_Lane_Assignment_V: implementation-data-type=boolean
        OBJ_Top_Out_Of_Image_V: implementation-data-type=boolean
        OBJ_Bottom_Out_Of_Image_V: implementation-data-type=boolean
        OBJ_Age_Seconds_V: implementation-data-type=boolean
        OBJ_Width_V: implementation-data-type=boolean
        OBJ_Length_V: implementation-data-type=boolean
        OBJ_Height_V: implementation-data-type=boolean
        OBJ_Absolute_Long_Velocity_V: implementation-data-type=boolean
        PaddingGap8_4: implementation-data-type=uint8
        OBJ_Abs_Long_Velocity_STD: implementation-data-type=float32
        OBJ_Absolute_Lat_Velocity_V: implementation-data-type=boolean
        OBJ_Absolute_Lat_Acc_V: implementation-data-type=boolean
        OBJ_Absolute_Acceleration_V: implementation-data-type=boolean
        OBJ_Inv_TTC_V: implementation-data-type=boolean
        OBJ_Inv_TTC: implementation-data-type=float32
        OBJ_Relative_Long_Velocity_V: implementation-data-type=boolean
        OBJ_Relative_Lat_Velocity_V: implementation-data-type=boolean
        OBJ_Long_Distance_V: implementation-data-type=boolean
        OBJ_Lat_Distance_V: implementation-data-type=boolean
        OBJ_Absolute_Speed_V: implementation-data-type=boolean
        OBJ_Heading_V: implementation-data-type=boolean
        PaddingGap16_5: implementation-data-type=uint16
        OBJ_Absolute_Speed_STD: implementation-data-type=float32
        OBJ_Heading_STD: implementation-data-type=float32
        OBJ_Angle_Rate_V: implementation-data-type=boolean
        OBJ_Angle_Right_V: implementation-data-type=boolean
        OBJ_Angle_Left_V: implementation-data-type=boolean
        OBJ_Angle_Side_V: implementation-data-type=boolean
        OBJ_Angle_Side_STD: implementation-data-type=float32
        OBJ_Angle_Mid_V: implementation-data-type=boolean
        OBJ_Is_In_Drivable_Area_V: implementation-data-type=boolean
        OBJ_Is_VeryClose_V: implementation-data-type=boolean
        Reserved: implementation-data-type=Dt_ARRAY_14_uint8
        PaddingGap8_6: implementation-data-type=uint8
        PaddingGap16_7: implementation-data-type=uint16
        OBJ_Absolute_Acce_STD: implementation-data-type=float32
    Dt_RECORD_MeObjects_E: category=STRUCTURE
      element stHeader: implementation-data-type=Dt_RECORD_HEADER
      element stObjCommon: implementation-data-type=Dt_RECORD_ObjCommon
      element gstMeObject: implementation-data-type=Dt_ARRAY_20_MeObject
    Dt_RECORD_MeObjects_E_x: category=STRUCTURE
      element stHeader: implementation-data-type=Dt_RECORD_HEADER
      element stObjCommon: implementation-data-type=Dt_RECORD_ObjCommon
      element gstMeObject: implementation-data-type=Dt_ARRAY_5_MeObject
    Dt_RECORD_MeSematicLines_E: category=STRUCTURE
      element stHeader: implementation-data-type=Dt_RECORD_HEADER
      element stSLCommon: implementation-data-type=Dt_RECORD_SLCommon
      element gstSematicLine: implementation-data-type=Dt_ARRAY_10_SematicLine
    Dt_RECORD_MeSematicMark_E: category=STRUCTURE
      element stSMCommon: implementation-data-type=Dt_RECORD_SMCommon
      element gstSematicMark: implementation-data-type=Dt_ARRAY_20_SematicMark
      element stHeader: implementation-data-type=Dt_RECORD_HEADER
    Dt_RECORD_MeTFL_E: category=STRUCTURE
      element gstrTFL: implementation-data-type=Dt_ARRAY_10_TFL
      element strTFLCommon: implementation-data-type=Dt_RECORD_TFLCommon
      element stHeader: implementation-data-type=Dt_RECORD_HEADER
    Dt_RECORD_MeTSR_E: category=STRUCTURE
      element strTSRCommon: implementation-data-type=Dt_RECORD_TSRCommon
      element gstrTSR: implementation-data-type=Dt_ARRAY_20_TSR
      element stHeader: implementation-data-type=Dt_RECORD_HEADER
    Dt_RECORD_MeTSR_E_x: category=STRUCTURE
      element strTSRCommon: implementation-data-type=Dt_RECORD_TSRCommon
      element gstrTSR: implementation-data-type=Dt_ARRAY_10_TSR
      element stHeader: implementation-data-type=Dt_RECORD_HEADER
    Dt_RECORD_NavStatus_Heading: category=STRUCTURE
      4 x element, all with category=TYPE_REFERENCE:
        ChannelInfosecinfo: implementation-data-type=uint8
        CurrentGPSTimesecinfo: implementation-data-type=uint16
        Headingsecinfo: implementation-data-type=float32
        NavStatussecinfo: implementation-data-type=uint8
    Dt_RECORD_ObjCommon: category=STRUCTURE
      13 x element, all with category=TYPE_REFERENCE:
        OBJ_Zero_byte: implementation-data-type=uint8
        OBJ_Protocol_Version: implementation-data-type=uint8
        OBJ_Sync_ID: implementation-data-type=uint8
        OBJ_VRU_Count: implementation-data-type=uint8
        OBJ_VD_Count: implementation-data-type=uint8
        OBJ_General_OBJ_Count: implementation-data-type=uint8
        OBJ_Animal_Count: implementation-data-type=uint8
        OBJ_VD_CIPV_ID: implementation-data-type=uint8
        OBJ_VD_CIPV_Lost: implementation-data-type=uint8
        OBJ_VD_Allow_Acce: implementation-data-type=uint8
        OBJ_VD_NIV_Right: implementation-data-type=uint8
        OBJ_VD_NIV_Left: implementation-data-type=uint8
        OBJ_Header_Buffer: implementation-data-type=uint32
    Dt_RECORD_Pitch_Roll: category=STRUCTURE
      element Pitchsecinfo: implementation-data-type=float32
      element Rollsecinfo: implementation-data-type=float32
    Dt_RECORD_PoserrStatus1: category=STRUCTURE
      element AltStdsecinfo: implementation-data-type=float32
      element LatStdsecinfo: implementation-data-type=float32
      element LonStdsecinfo: implementation-data-type=float32
    Dt_RECORD_RoadEdgeCommon: category=STRUCTURE
      7 x element, all with category=TYPE_REFERENCE:
        LS_Road_Edge_Zero_byte: implementation-data-type=uint8
        LS_Road_Edge_Protocol_Version: implementation-data-type=uint8
        LS_Road_Edge_Sync_ID: implementation-data-type=uint8
        LS_Road_Edge_Number: implementation-data-type=uint8
        LS_Road_Edge_Header_Buffer: implementation-data-type=uint8
        PaddingGap8_1: implementation-data-type=uint8
        PaddingGap16_2: implementation-data-type=uint16
    Dt_RECORD_SematicLine: category=STRUCTURE
      21 x element, all with category=TYPE_REFERENCE:
        SL_Long_Dist: implementation-data-type=float32
        SL_Long_Dist_STD: implementation-data-type=float32
        SL_Probability: implementation-data-type=float32
        SL_Is_Relevant: implementation-data-type=boolean
        PaddingGap8_1: implementation-data-type=uint8
        PaddingGap16_2: implementation-data-type=uint16
        SL_Width: implementation-data-type=float32
        SL_Length: implementation-data-type=float32
        SL_Measure_Status: implementation-data-type=uint8
        PaddingGap8_3: implementation-data-type=uint8
        PaddingGap16_4: implementation-data-type=uint16
        SL_Angle: implementation-data-type=float32
        SL_Angle_STD: implementation-data-type=float32
        SL_Close_To_Junc: implementation-data-type=boolean
        PaddingGap8_5: implementation-data-type=uint8
        PaddingGap16_6: implementation-data-type=uint16
        SL_Lat_Distance: implementation-data-type=float32
        SL_Color: implementation-data-type=uint8
        SL_Type: implementation-data-type=uint8
        SL_ID: implementation-data-type=uint8
        PaddingGap8_7: implementation-data-type=uint8
    Dt_RECORD_SematicMark: category=STRUCTURE
      12 x element, all with category=TYPE_REFERENCE:
        SM_ID: implementation-data-type=uint8
        PaddingGap8_1: implementation-data-type=uint8
        PaddingGap16_2: implementation-data-type=uint16
        SM_Type: implementation-data-type=float32
        Reserved_2: implementation-data-type=uint8
        PaddingGap8_3: implementation-data-type=uint8
        PaddingGap16_4: implementation-data-type=uint16
        SM_Lat_Distance: implementation-data-type=float32
        SM_Long_Distance: implementation-data-type=float32
        SM_Confidence: implementation-data-type=float32
        SM_Buffer: implementation-data-type=uint16
        PaddingGap16_5: implementation-data-type=uint16
    Dt_RECORD_SL_Descrip_E: category=STRUCTURE
      element gstSLD: implementation-data-type=Dt_ARRAY_10_SLD
      element stSLDCommon: implementation-data-type=Dt_RECORD_SLDCommon
      element stHeader: implementation-data-type=Dt_RECORD_HEADER
    Dt_RECORD_SLCommon: category=STRUCTURE
      7 x element, all with category=TYPE_REFERENCE:
        SL_Zero_byte: implementation-data-type=uint8
        SL_Protocol_Version: implementation-data-type=uint8
        SL_Sync_ID: implementation-data-type=uint8
        SL_Approved_Lines: implementation-data-type=uint8
        SL_Header_Buffer: implementation-data-type=uint8
        PaddingGap8_1: implementation-data-type=uint8
        PaddingGap16_2: implementation-data-type=uint16
    Dt_RECORD_SLD: category=STRUCTURE
      17 x element, all with category=TYPE_REFERENCE:
        SLD_Existence_Probability: implementation-data-type=float32
        SLD_NonExistence_Probability: implementation-data-type=float32
        SLD_Role: implementation-data-type=uint8
        SLD_View: implementation-data-type=uint8
        SLD_Orientation: implementation-data-type=uint8
        PaddingGap8_1: implementation-data-type=uint8
        SLD_Orientation_Probability: implementation-data-type=float32
        SLD_Direction: implementation-data-type=uint8
        PaddingGap8_2: implementation-data-type=uint8
        PaddingGap16_3: implementation-data-type=uint16
        SLD_Direction_Probability: implementation-data-type=float32
        SLD_Type: implementation-data-type=uint16
        PaddingGap16_4: implementation-data-type=uint16
        SLD_Type_Probability: implementation-data-type=float32
        SLD_Buffer: implementation-data-type=uint8
        Reserved_2: implementation-data-type=boolean
        PaddingGap16_5: implementation-data-type=uint16
    Dt_RECORD_SLDCommon: category=STRUCTURE
      17 x element, all with category=TYPE_REFERENCE:
        SLD_Num_Of_Lanes_Far_Left: implementation-data-type=uint8
        SLD_Num_Of_Lanes_Far_Right: implementation-data-type=uint8
        SLD_Has_Shoulder_Right_Close: implementation-data-type=boolean
        PaddingGap8_1: implementation-data-type=uint8
        SLD_Shoulder_Right_Width_Close: implementation-data-type=float32
        SLD_Has_Shoulder_Right_Far: implementation-data-type=boolean
        PaddingGap8_2: implementation-data-type=uint8
        PaddingGap16_3: implementation-data-type=uint16
        SLD_Shoulder_Right_Width_Far: implementation-data-type=float32
        SLD_Header_Buffer: implementation-data-type=uint8
        SLD_Zero_byte: implementation-data-type=uint8
        SLD_Protocol_Version: implementation-data-type=uint8
        SLD_Sync_ID: implementation-data-type=uint8
        SLD_Num_Of_Lanes_Close_Left: implementation-data-type=uint8
        SLD_Num_Of_Lanes_Close_Right: implementation-data-type=uint8
        Reserved_1: implementation-data-type=uint8
        PaddingGap8_4: implementation-data-type=uint8
    Dt_RECORD_SMCommon: category=STRUCTURE
      7 x element, all with category=TYPE_REFERENCE:
        SM_Zero_byte: implementation-data-type=uint8
        SM_Protocol_Version: implementation-data-type=uint8
        SM_Sync_ID: implementation-data-type=uint8
        SM_Header_Buffer: implementation-data-type=uint8
        SM_Approved_Marks: implementation-data-type=uint8
        PaddingGap8_1: implementation-data-type=uint8
        PaddingGap16_2: implementation-data-type=uint16
    Dt_RECORD_StatusInfo: category=STRUCTURE
      7 x element, all with category=TYPE_REFERENCE:
        ECUDelaysecinfo: implementation-data-type=uint8
        ECUFreqsecinfo: implementation-data-type=uint8
        GPSDelaysecinfo: implementation-data-type=uint8
        GPSFreqsecinfo: implementation-data-type=uint8
        INSDelaysecinfo: implementation-data-type=uint16
        INSStatussecinfo: implementation-data-type=uint8
        INSWarningsecinfo: implementation-data-type=uint8
    Dt_RECORD_TAC2: category=STRUCTURE
      23 x element, all with category=TYPE_REFERENCE:
        TAC_Zero_byte: implementation-data-type=uint8
        TAC_Vision_Protocol_Version: implementation-data-type=uint8
        TAC_Mode: implementation-data-type=uint8
        TAC_BottomLeftSquare_0: implementation-data-type=uint8
        TAC_BottomLeftSquare_1: implementation-data-type=uint8
        TAC_Targets_Num: implementation-data-type=uint8
        Reserved_1: implementation-data-type=uint8
        PaddingGap8_1: implementation-data-type=uint8
        TAC_TargetInfo_Lat_Distance_0: implementation-data-type=float32
        TAC_TargetInfo_Lat_Distance_1: implementation-data-type=float32
        TAC_TargetInfo_Height_0: implementation-data-type=float32
        TAC_targetInfo_height_1: implementation-data-type=float32
        TAC_Camera_Height: implementation-data-type=float32
        TAC_Camera_Z: implementation-data-type=float32
        TAC_Max_Horizon: implementation-data-type=uint8
        TAC_Min_Horizon: implementation-data-type=sint8
        TAC_Max_Yaw: implementation-data-type=uint8
        TAC_Min_Yaw: implementation-data-type=sint8
        TAC_Max_RollAngle: implementation-data-type=float32
        TAC_SquareSideSize: implementation-data-type=float32
        TAC_Bottom: implementation-data-type=sint8
        Reserved_2: implementation-data-type=uint8
        PaddingGap16_2: implementation-data-type=uint16
    Dt_RECORD_TFL: category=STRUCTURE
      27 x element, all with category=TYPE_REFERENCE:
        TFL_Existence_Probability: implementation-data-type=float32
        TFL_Relevance_Probability: implementation-data-type=float32
        TFL_Color: implementation-data-type=uint8
        TFL_Mode: implementation-data-type=uint8
        TFL_Relevance_Direction: implementation-data-type=uint8
        Reserved_1: implementation-data-type=uint8
        TFL_Rel_Dir_Quality: implementation-data-type=float32
        TFL_Shape: implementation-data-type=uint8
        TFL_Structure_Orientation: implementation-data-type=uint8
        PaddingGap16_1: implementation-data-type=uint16
        TFL_Rel_Height: implementation-data-type=float32
        TFL_Rel_Height_STD: implementation-data-type=float32
        TFL_Lat_Distance: implementation-data-type=float32
        TFL_Lat_Distance_STD: implementation-data-type=float32
        TFL_Long_Distance: implementation-data-type=float32
        TFL_Long_Distance_STD: implementation-data-type=float32
        TFL_Width: implementation-data-type=float32
        TFL_Height: implementation-data-type=float32
        TFL_Width_STD: implementation-data-type=float32
        TFL_Height_STD: implementation-data-type=float32
        TFL_Camera_Source: implementation-data-type=uint8
        TFL_Object_ID: implementation-data-type=uint8
        TFL_LightBox_ID: implementation-data-type=uint8
        Reserved_2: implementation-data-type=boolean
        Reserved_3: implementation-data-type=uint8
        PaddingGap8_2: implementation-data-type=uint8
        PaddingGap16_3: implementation-data-type=uint16
    Dt_RECORD_TFLCommon: category=STRUCTURE
      7 x element, all with category=TYPE_REFERENCE:
        TFL_Zero_byte: implementation-data-type=uint8
        TFL_Protocol_Version: implementation-data-type=uint8
        TFL_Sync_ID: implementation-data-type=uint8
        TFL_Number_Of_Objects: implementation-data-type=uint8
        TFL_Header_Buffer: implementation-data-type=uint8
        PaddingGap8_1: implementation-data-type=uint8
        PaddingGap16_2: implementation-data-type=uint16
    Dt_RECORD_TSR: category=STRUCTURE
      42 x element, all with category=TYPE_REFERENCE:
        TSR_ID: implementation-data-type=uint8
        TSR_Camera_Source: implementation-data-type=uint8
        PaddingGap16_1: implementation-data-type=uint16
        TSR_Sign_Name: implementation-data-type=float32
        TSR_Relevancy: implementation-data-type=uint8
        TSR_Filter_Type: implementation-data-type=uint8
        Reserved_3: implementation-data-type=boolean
        TSR_Sup1_SignName: implementation-data-type=uint8
        TSR_Sup1_Confidence: implementation-data-type=float32
        TSR_Sup2_SignName: implementation-data-type=uint8
        PaddingGap8_2: implementation-data-type=uint8
        PaddingGap16_3: implementation-data-type=uint16
        TSR_Sup2_Confidence: implementation-data-type=float32
        Reserved_4: implementation-data-type=uint8
        TSR_Sign_Shape: implementation-data-type=uint8
        TSR_Sign_Structure: implementation-data-type=uint8
        PaddingGap8_4: implementation-data-type=uint8
        TSR_Confidence: implementation-data-type=float32
        TSR_Sign_Long_Distance: implementation-data-type=float32
        Reserved_5: implementation-data-type=uint32
        TSR_Sign_Lateral_Distance: implementation-data-type=float32
        TSR_Sign_Height: implementation-data-type=float32
        Reserved_6: implementation-data-type=uint8
        PaddingGap8_5: implementation-data-type=uint8
        PaddingGap16_6: implementation-data-type=uint16
        TSR_Sign_Long_Distance_STD: implementation-data-type=float32
        TSR_Sign_Lat_Distance_STD: implementation-data-type=float32
        Reserved_7: implementation-data-type=uint8
        PaddingGap8_7: implementation-data-type=uint8
        PaddingGap16_8: implementation-data-type=uint16
        TSR_Sign_Height_STD: implementation-data-type=float32
        TSR_Sign_Panel_Width: implementation-data-type=float32
        Reserved_8: implementation-data-type=uint8
        PaddingGap8_9: implementation-data-type=uint8
        PaddingGap16_10: implementation-data-type=uint16
        TSR_Sign_Panel_Height: implementation-data-type=float32
        TSR_Sign_Panel_Width_STD: implementation-data-type=float32
        TSR_Sign_Panel_Height_STD: implementation-data-type=float32
        Reserved_9: implementation-data-type=uint8
        PaddingGap8_11: implementation-data-type=uint8
        PaddingGap16_12: implementation-data-type=uint16
        TSR_Tracking_Age: implementation-data-type=uint32
    Dt_RECORD_TSRCommon: category=STRUCTURE
      10 x element, all with category=TYPE_REFERENCE:
        Zero_byte: implementation-data-type=uint8
        TSR_Protocol_Version: implementation-data-type=uint8
        TSR_Sync_ID: implementation-data-type=uint8
        Reserved_1: implementation-data-type=uint8
        TSR_APR_Sign_Count: implementation-data-type=uint8
        TSR_Filtered_Sign_Count: implementation-data-type=uint8
        TSR_UnderTracking_Sign_Count: implementation-data-type=uint16
        TSR_Header_Buffer: implementation-data-type=uint8
        PaddingGap8_1: implementation-data-type=uint8
        PaddingGap16_2: implementation-data-type=uint16
    Dt_RECORD_VCUStatus_reserved5: category=STRUCTURE
      element Byte9: implementation-data-type=uint32
      element Byte8: implementation-data-type=uint32
    Dt_RECORD_VCUStatus_reserved6: category=STRUCTURE
      element Byte11: implementation-data-type=uint32
      element Byte10: implementation-data-type=uint32
    Dt_RECORD_VCUStatus1: category=STRUCTURE
      8 x element, all with category=TYPE_REFERENCE:
        DrivemModeStssecinfo: implementation-data-type=uint8
        DriveModeReqsecinfo: implementation-data-type=boolean
        EnSpdsecinfo: implementation-data-type=float32
        EPSMotOtptToqsecinfo: implementation-data-type=float32
        keep1secinfo: implementation-data-type=float32
        PtBrkPdlDscrtInptStssecinfo: implementation-data-type=boolean
        PtBrkPdlDscrtInptStsVsecinfo: implementation-data-type=boolean
        SCUShiferLvrPossecinfo: implementation-data-type=uint8
    Dt_RECORD_VCUStatus10: category=STRUCTURE
      8 x element, all with category=TYPE_REFERENCE:
        RNonDrvnWhlRotlDistVHSC2: implementation-data-type=boolean
        RNonDrvnWhlRotlDistPCHSC2: implementation-data-type=uint16
        RDrvnWhlRotlDistVHSC2: implementation-data-type=boolean
        RDrvnWhlRotlDistPlsCtrHSC2: implementation-data-type=uint16
        LDrvnWhlRotlDistVHSC2: implementation-data-type=boolean
        LNonDrvnWhlRotlDistPCHSC2: implementation-data-type=uint16
        LNonDrvnWhlRotlDistVHSC2: implementation-data-type=boolean
        LDrvnWhlRotlDistPlsCtrHSC2: implementation-data-type=uint16
    Dt_RECORD_VCUStatus2: category=STRUCTURE
      10 x element, all with category=TYPE_REFERENCE:
        StrgWhlAngHSC4: implementation-data-type=float32
        StrgWhlAngAlvRCHSC4: implementation-data-type=uint8
        StrgWhlAngExtdPVHSC4: implementation-data-type=uint16
        StrgWhlAngGrdHSC4: implementation-data-type=sint16
        StrgWhlAngSnsrCalStsHSC4: implementation-data-type=uint8
        StrgWhlAngSnsrChksmHSC4: implementation-data-type=uint8
        StrgWhlAngSnsrFltHSC4: implementation-data-type=boolean
        StrgWhlAngSnsrInidHSC4: implementation-data-type=boolean
        StrgWhlAngSnsrMultCapbHSC4: implementation-data-type=boolean
        StrgWhlAngVHSC4: implementation-data-type=boolean
    Dt_RECORD_VCUStatus3: category=STRUCTURE
      9 x element, all with category=TYPE_REFERENCE:
        SysVol_HSC4: implementation-data-type=float32
        EPBAppcnStsHSC4: implementation-data-type=uint8
        VehSpdAvgVHSC4: implementation-data-type=boolean
        VehSpdAvgHSC4: implementation-data-type=float32
        VSELongtAccVHSC4: implementation-data-type=boolean
        VSELongtAccHSC4: implementation-data-type=float32
        VehDynYawRateVHSC4: implementation-data-type=boolean
        VehDynYawRateHSC4: implementation-data-type=float32
        AirbagDplHSC4: implementation-data-type=boolean
    Dt_RECORD_VCUStatus4: category=STRUCTURE
      7 x element, all with category=TYPE_REFERENCE:
        VehLckngStaHSC4: implementation-data-type=boolean
        FrtPsngDoorOpenStsHSC4: implementation-data-type=uint8
        DrvrDoorOpenStsHSC4: implementation-data-type=uint8
        VehInertiaSwTrigdHSC4: implementation-data-type=boolean
        BrkPdlDrvrAppdPrsV_HSC4: implementation-data-type=boolean
        BrkPdlDrvrAppdPrsAlvRC_HSC4: implementation-data-type=uint8
        BrkPdlDrvrAppdPrs_HSC4: implementation-data-type=uint8
    Dt_RECORD_VCUStatus5: category=STRUCTURE
      5 x element, all with category=TYPE_REFERENCE:
        VehDeceLmtHSC4: implementation-data-type=float32
        VehAcceLmtHSC4: implementation-data-type=float32
        StrgWhlAngLmtHSC4: implementation-data-type=float32
        StrgWhlAngGrdLmtHSC4: implementation-data-type=sint16
        RdFrictionCoefficientHSC4: implementation-data-type=float32
    Dt_RECORD_VCUStatus6: category=STRUCTURE
      8 x element, all with category=TYPE_REFERENCE:
        WhlGndVelLDrvnsecinfo: implementation-data-type=float32
        WhlGndVelLDrvnVsecinfo: implementation-data-type=boolean
        WhlGndVelLNonDrvnsecinfo: implementation-data-type=float32
        WhlGndVelLNonDrvnVsecinfo: implementation-data-type=boolean
        WhlGndVelRDrvnsecinfo: implementation-data-type=float32
        WhlGndVelRDrvnVsecinfo: implementation-data-type=boolean
        WhlGndVelRNonDrvnsecinfo: implementation-data-type=float32
        WhlGndVelRNonDrvnVsecinfo: implementation-data-type=boolean
    Dt_RECORD_VCUStatus7: category=STRUCTURE
      19 x element, all with category=TYPE_REFERENCE:
        ACInCarTemHSC4: implementation-data-type=float32
        FuelLvlPcntVHSC4: implementation-data-type=boolean
        FuelLvlPcntHSC4: implementation-data-type=float32
        AmbtLghtLvlHSC4: implementation-data-type=uint8
        OtsdAirTemCrValV_HSC4: implementation-data-type=boolean
        OtsdAirTemCrVal_HSC4: implementation-data-type=float32
        BrkLghtsStaHSC4: implementation-data-type=boolean
        DangerousWrnngLghtStaHSC4: implementation-data-type=boolean
        DipdBeamLampsStaHSC4: implementation-data-type=boolean
        FrtFogLampStaHSC4: implementation-data-type=boolean
        HornStaHSC4: implementation-data-type=boolean
        LDircnLampsStaHSC4: implementation-data-type=boolean
        MainBeamLampsStaHSC4: implementation-data-type=boolean
        RDircnLampsStaHSC4: implementation-data-type=boolean
        RevsngLghtStaHSC4: implementation-data-type=boolean
        RrFogLampStaHSC4: implementation-data-type=boolean
        WidthLampAndTaillightStateHSC4: implementation-data-type=boolean
        WiperStaHSC4: implementation-data-type=uint8
        WshrStaHSC4: implementation-data-type=boolean
    Dt_RECORD_VCUStatus8: category=STRUCTURE
      7 x element, all with category=TYPE_REFERENCE:
        TimeDspFmtHSC2: implementation-data-type=boolean
        SecsOfMinuteHSC2: implementation-data-type=uint8
        MinuteOfHourHSC2: implementation-data-type=uint8
        HourOfDayHSC2: implementation-data-type=uint8
        CalendarYearHSC5: implementation-data-type=uint8
        CalendarMonthHSC2: implementation-data-type=uint8
        CalendarDayHSC2: implementation-data-type=uint8
    Dt_RECORD_VCUStatus9: category=STRUCTURE
      7 x element, all with category=TYPE_REFERENCE:
        VCUMainID: implementation-data-type=uint8
        VCUAddonsID: implementation-data-type=uint8
        Vehicleplatform: implementation-data-type=uint8
        VCUstage: implementation-data-type=uint8
        Projectname: implementation-data-type=uint8
        Component: implementation-data-type=uint8
        VehOdoHSC2: implementation-data-type=uint32
    Dt_RECORD_VCUStatusTest1: category=STRUCTURE
      4 x element, all with category=TYPE_REFERENCE, implementation-data-type=float32:
        Test4
        Test3
        Test2
        Test1
    Dt_RECORD_VCUStatusTest2: category=STRUCTURE
      4 x element, all with category=TYPE_REFERENCE, implementation-data-type=float32:
        Test8
        Test7
        Test6
        Test5
    Dt_RECORD_VCUStatusTest3: category=STRUCTURE
      4 x element, all with category=TYPE_REFERENCE, implementation-data-type=float32:
        Test12
        Test11
        Test10
        Test9
    Dt_RECORD_VCUStatusTest4: category=STRUCTURE
      4 x element, all with category=TYPE_REFERENCE, implementation-data-type=sint16:
        Test16
        Test15
        Test14
        Test13
    Dt_RECORD_VelNorthEast: category=STRUCTURE
      element EastVelocitysecinfo: implementation-data-type=float32
      element NorthVelocitysecinfo: implementation-data-type=float32
    Dt_RECORD_VersionNumber: category=STRUCTURE
      4 x element, all with category=TYPE_REFERENCE, implementation-data-type=uint16:
        ARMAPPVersecinfo
        ARMBLVersecinfo
        DSPAPPVersecinfo
        DSPBLVersecinfo
package /PortInterfaces
  45 x sender receiver interface:
    PiCom_AccBias_Lcc_100ms: invalidation-policy{data-element=DeAccBias_Lcc, handle-invalid=DONT-INVALIDATE}
      data DeAccBias_Lcc: type=Dt_RECORD_AccBias_Lcc
    PiCom_Diagnosticmessage_IMU_1000ms: invalidation-policy{data-element=DeDiagnosticmessage_IMU, handle-invalid=DONT-INVALIDATE}
      data DeDiagnosticmessage_IMU: type=Dt_RECORD_Diagnosticmessage_IMU
    PiCom_GPS_ECUStatus_100ms: invalidation-policy{data-element=DeGPS_ECUStatus, handle-invalid=DONT-INVALIDATE}
      data DeGPS_ECUStatus: type=Dt_RECORD_GPS_ECUStatus
    PiCom_GPSPos_HeadingPrecison_100ms: invalidation-policy{data-element=DeGPSPos_HeadingPrecison, handle-invalid=DONT-INVALIDATE}
      data DeGPSPos_HeadingPrecison: type=Dt_RECORD_GPSPos_HeadingPrecison
    PiCom_GPSVel_PitchPrecison_100ms: invalidation-policy{data-element=DeGPSVel_PitchPrecison, handle-invalid=DONT-INVALIDATE}
      data DeGPSVel_PitchPrecison: type=Dt_RECORD_GPSVel_PitchPrecison
    PiCom_InertialNavigation_10ms: invalidation-policy{data-element=DeInertialNavigation, handle-invalid=DONT-INVALIDATE}
      data DeInertialNavigation: type=Dt_RECORD_InertialNavigation
    PiCom_INSATB_100ms: invalidation-policy{data-element=DeINSATB, handle-invalid=DONT-INVALIDATE}
      data DeINSATB: type=Dt_RECORD_INSATB
    PiCom_INSATG_100ms: invalidation-policy{data-element=DeINSATG, handle-invalid=DONT-INVALIDATE}
      data DeINSATG: type=Dt_RECORD_INSATG
    PiCom_INSLTC_LTG_100ms: invalidation-policy{data-element=DeINSLTC_LTG, handle-invalid=DONT-INVALIDATE}
      data DeINSLTC_LTG: type=Dt_RECORD_INSLTC_LTG
    PiCom_VersionNumber_100ms: invalidation-policy{data-element=DeVersionNumber, handle-invalid=DONT-INVALIDATE}
      data DeVersionNumber: type=Dt_RECORD_VersionNumber
    PiEyeQCom_50ms
      12 x data:
        DeMeCommon_E: type=Dt_RECORD_MeCommon_E
        DeMeConstructionArea_E: type=Dt_RECORD_ConstructionArea_E
        DeMeHLB_E: type=Dt_RECORD_HLB_E
        DeMeLane_Support_E: type=Dt_RECORD_Lane_Support_E
        DeMeLaneAssignment_E: type=Dt_RECORD_MeLaneAssignment
        DeMeLDW_E: type=Dt_RECORD_LDW_E
        DeMeLS_ADV_E: type=Dt_RECORD_MeLS_ADV_E
        DeMeLS_Road_Edge_E: type=Dt_RECORD_LS_Road_Edge_E
        DeMeSematicLines_E: type=Dt_RECORD_MeSematicLines_E
        DeMeSematicMarks_E: type=Dt_RECORD_MeSematicMark_E
        DeMeSL_Descrip_E: type=Dt_RECORD_SL_Descrip_E
        DeRequestCalibrationStatus: type=uint8
      invalidation-policys:
        data-element=DeMeCommon_E, handle-invalid=DONT-INVALIDATE
        data-element=DeMeConstructionArea_E, handle-invalid=DONT-INVALIDATE
        data-element=DeMeHLB_E, handle-invalid=DONT-INVALIDATE
        data-element=DeMeLane_Support_E, handle-invalid=DONT-INVALIDATE
        data-element=DeMeLaneAssignment_E, handle-invalid=DONT-INVALIDATE
        data-element=PiEyeQCom_50ms/DeMeLDW_E, handle-invalid=DONT-INVALIDATE
        data-element=DeMeLS_ADV_E, handle-invalid=DONT-INVALIDATE
        data-element=DeMeLS_Road_Edge_E, handle-invalid=DONT-INVALIDATE
        data-element=DeMeSematicLines_E, handle-invalid=DONT-INVALIDATE
        data-element=DeMeSematicMarks_E, handle-invalid=DONT-INVALIDATE
        data-element=DeMeSL_Descrip_E, handle-invalid=DONT-INVALIDATE
        data-element=DeRequestCalibrationStatus, handle-invalid=DONT-INVALIDATE
    PiEyeQCom_FreeSpace_50ms
      6 x data:
        DeMeFreeSpace_E: type=Dt_RECORD_MeFreeSpace_E
        DeMeFreeSpace_E_{1..5}: type=Dt_RECORD_MeFreeSpace_E_x
      invalidation-policys:
        data-element=DeMeFreeSpace_E, handle-invalid=DONT-INVALIDATE
        data-element=DeMeFreeSpace_E_{1..5}, handle-invalid=DONT-INVALIDATE
    PiEyeQCom_LDW_50ms: invalidation-policy{data-element=PiEyeQCom_LDW_50ms/DeMeLDW_E, handle-invalid=DONT-INVALIDATE}
      data DeMeLDW_E: type=Dt_RECORD_MeLDW_E
    PiEyeQCom_Object_50ms
      5 x data:
        DeMeObjects_E: type=Dt_RECORD_MeObjects_E
        DeMeObjects_E_{1..4}: type=Dt_RECORD_MeObjects_E_x
      invalidation-policys:
        data-element=DeMeObjects_E, handle-invalid=DONT-INVALIDATE
        data-element=DeMeObjects_E_{1..4}, handle-invalid=DONT-INVALIDATE
    PiEyeQCom_TFL_100ms: invalidation-policy{data-element=DeMeTFL, handle-invalid=DONT-INVALIDATE}
      data DeMeTFL: type=Dt_RECORD_MeTFL_E
    PiEyeQCom_TSR_100ms
      data DeMeTSR: type=Dt_RECORD_MeTSR_E
      data DeMeTSR_1: type=Dt_RECORD_MeTSR_E_x
      data DeMeTSR_2: type=Dt_RECORD_MeTSR_E_x
      invalidation-policys:
        data-element=DeMeTSR, handle-invalid=DONT-INVALIDATE
        data-element=DeMeTSR_1, handle-invalid=DONT-INVALIDATE
        data-element=DeMeTSR_2, handle-invalid=DONT-INVALIDATE
    PiMeProcess_50ms
      data DeCurrentMode: type=Dt_RECORD_CurrentMode
      data DeStartCalibration: type=boolean
      invalidation-policys:
        data-element=DeCurrentMode, handle-invalid=DONT-INVALIDATE
        data-element=DeStartCalibration, handle-invalid=DONT-INVALIDATE
    PiMeProcess_Init2EyeQ_50ms
      5 x data:
        DeCodingEnviroment: type=Dt_RECORD_CodingEnviroment
        DeIintISPCCoreVision: type=Dt_RECORD_IintISPCCoreVision
        DeInitEnvironment: type=Dt_RECORD_InitEnvironment
        DeInitGENERAL: type=Dt_RECORD_InitGENERAL
        DeInitTAC2: type=Dt_RECORD_TAC2
      invalidation-policys:
        data-element=DeCodingEnviroment, handle-invalid=DONT-INVALIDATE
        data-element=DeIintISPCCoreVision, handle-invalid=DONT-INVALIDATE
        data-element=DeInitEnvironment, handle-invalid=DONT-INVALIDATE
        data-element=DeInitGENERAL, handle-invalid=DONT-INVALIDATE
        data-element=DeInitTAC2, handle-invalid=DONT-INVALIDATE
    PiVMS_ETC1_10ms: invalidation-policy{data-element=DeETC1, handle-invalid=DONT-INVALIDATE}
      data DeETC1: type=Dt_RECORD_ETC1
    PiVMS_iECU_250h_10ms: invalidation-policy{data-element=DeiECU_250h, handle-invalid=DONT-INVALIDATE}
      data DeiECU_250h: type=Dt_RECORD_iECU_250h
    PiVMS_iECU_255h_100ms: invalidation-policy{data-element=DeiECU_255h, handle-invalid=DONT-INVALIDATE}
      data DeiECU_255h: type=Dt_RECORD_iECU_255h
    PiVMS_iECU_256h_100ms: invalidation-policy{data-element=DeiECU_256h, handle-invalid=DONT-INVALIDATE}
      data DeiECU_256h: type=Dt_RECORD_iECU_256h
    PiVMS_iECU_25Ah_100ms: invalidation-policy{data-element=DeiECU_25Ah, handle-invalid=DONT-INVALIDATE}
      data DeiECU_25Ah: type=Dt_RECORD_iECU_25Ah
    PiVMS_IECU_25Bh_100ms: invalidation-policy{data-element=DeIECU_25Bh, handle-invalid=DONT-INVALIDATE}
      data DeIECU_25Bh: type=Dt_RECORD_IECU_25Bh
    PiVMS_IECU_FMS1_100ms: invalidation-policy{data-element=DeIECU_FMS1, handle-invalid=DONT-INVALIDATE}
      data DeIECU_FMS1: type=Dt_RECORD_IECU_FMS1
    PiVMS_IECU_FMS2_100ms: invalidation-policy{data-element=DeIECU_FMS2, handle-invalid=DONT-INVALIDATE}
      data DeIECU_FMS2: type=Dt_RECORD_IECU_FMS2
    PiVMS_IECU1toPegasus_100ms: invalidation-policy{data-element=DeIECU1toPegasus, handle-invalid=DONT-INVALIDATE}
      data DeIECU1toPegasus: type=Dt_RECORD_IECU1toPegasus
    PiVMS_IECUInternal_100ms: invalidation-policy{data-element=DeIECUInternal, handle-invalid=DONT-INVALIDATE}
      data DeIECUInternal: type=Dt_RECORD_IECUInternal
    PiVMS_VCUStatus_reserved5_100ms: invalidation-policy{data-element=DeVCUStatus_reserved5, handle-invalid=DONT-INVALIDATE}
      data DeVCUStatus_reserved5: type=Dt_RECORD_VCUStatus_reserved5
    PiVMS_VCUStatus_reserved6_100ms: invalidation-policy{data-element=DeVCUStatus_reserved6, handle-invalid=DONT-INVALIDATE}
      data DeVCUStatus_reserved6: type=Dt_RECORD_VCUStatus_reserved6
    PiVMS_VCUStatus1_10ms: invalidation-policy{data-element=DeVCUStatus1, handle-invalid=DONT-INVALIDATE}
      data DeVCUStatus1: type=Dt_RECORD_VCUStatus1
    PiVMS_VCUStatus10_10ms: invalidation-policy{data-element=DeVCUStatus10, handle-invalid=DONT-INVALIDATE}
      data DeVCUStatus10: type=Dt_RECORD_VCUStatus10
    PiVMS_VCUStatus2_10ms: invalidation-policy{data-element=DeVCUStatus2, handle-invalid=DONT-INVALIDATE}
      data DeVCUStatus2: type=Dt_RECORD_VCUStatus2
    PiVMS_VCUStatus3_20ms: invalidation-policy{data-element=DeVCUStatus3, handle-invalid=DONT-INVALIDATE}
      data DeVCUStatus3: type=Dt_RECORD_VCUStatus3
    PiVMS_VCUStatus4_50ms: invalidation-policy{data-element=DeVCUStatus4, handle-invalid=DONT-INVALIDATE}
      data DeVCUStatus4: type=Dt_RECORD_VCUStatus4
    PiVMS_VCUStatus5_100ms: invalidation-policy{data-element=DeVCUStatus5, handle-invalid=DONT-INVALIDATE}
      data DeVCUStatus5: type=Dt_RECORD_VCUStatus5
    PiVMS_VCUStatus6_50ms: invalidation-policy{data-element=DeVCUStatus6, handle-invalid=DONT-INVALIDATE}
      data DeVCUStatus6: type=Dt_RECORD_VCUStatus6
    PiVMS_VCUStatus7_200ms: invalidation-policy{data-element=DeVCUStatus7, handle-invalid=DONT-INVALIDATE}
      data DeVCUStatus7: type=Dt_RECORD_VCUStatus7
    PiVMS_VCUStatus8_10ms: invalidation-policy{data-element=DeVCUStatus8, handle-invalid=DONT-INVALIDATE}
      data DeVCUStatus8: type=Dt_RECORD_VCUStatus8
    PiVMS_VCUStatus9_10ms: invalidation-policy{data-element=DeVCUStatus9, handle-invalid=DONT-INVALIDATE}
      data DeVCUStatus9: type=Dt_RECORD_VCUStatus9
    PiVMS_VCUStatusTest1_10ms: invalidation-policy{data-element=DeVCUStatusTest1, handle-invalid=DONT-INVALIDATE}
      data DeVCUStatusTest1: type=Dt_RECORD_VCUStatusTest1
    PiVMS_VCUStatusTest2_10ms: invalidation-policy{data-element=DeVCUStatusTest2, handle-invalid=DONT-INVALIDATE}
      data DeVCUStatusTest2: type=Dt_RECORD_VCUStatusTest2
    PiVMS_VCUStatusTest3_10ms: invalidation-policy{data-element=DeVCUStatusTest3, handle-invalid=DONT-INVALIDATE}
      data DeVCUStatusTest3: type=Dt_RECORD_VCUStatusTest3
    PiVMS_VCUStatusTest4_10ms: invalidation-policy{data-element=DeVCUStatusTest4, handle-invalid=DONT-INVALIDATE}
      data DeVCUStatusTest4: type=Dt_RECORD_VCUStatusTest4
    PiXavier_IDC_10ms: invalidation-policy{data-element=DeIDC, handle-invalid=DONT-INVALIDATE}
      data DeIDC: type=Dt_RECORD_IDC
